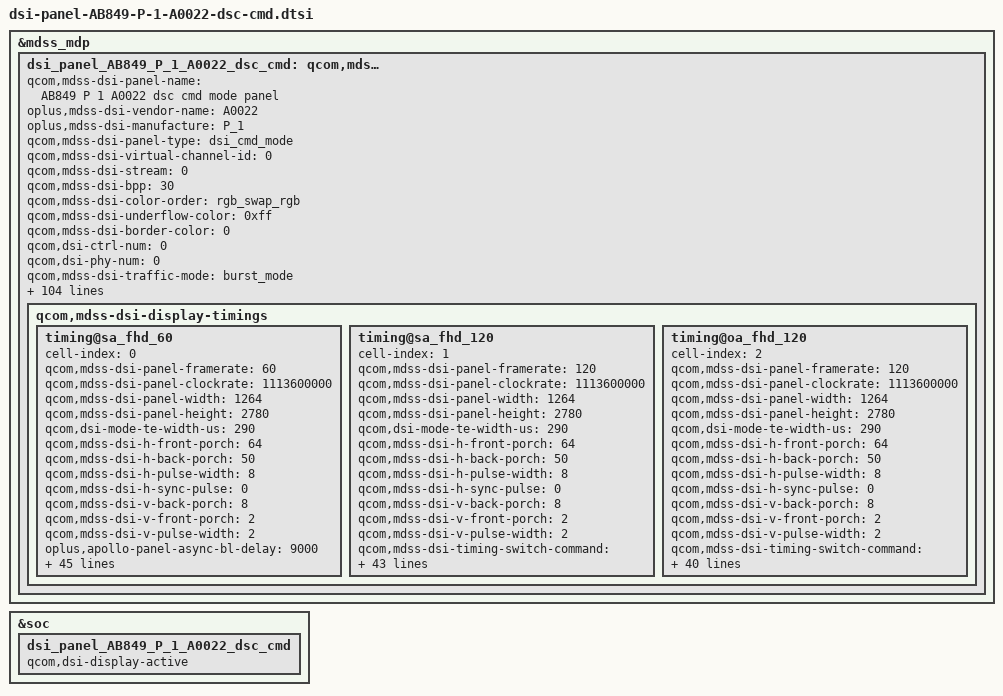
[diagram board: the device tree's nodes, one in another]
&mdss_mdp {
	dsi_panel_AB849_P_1_A0022_dsc_cmd: qcom,mdss_dsi_panel_AB849_P_1_A0022_dsc_cmd {
		qcom,mdss-dsi-panel-name = "AB849 P 1 A0022 dsc cmd mode panel";
		oplus,mdss-dsi-vendor-name = "A0022";
		oplus,mdss-dsi-manufacture = "P_1";
		qcom,mdss-dsi-panel-type = "dsi_cmd_mode";
		qcom,mdss-dsi-virtual-channel-id = <0>;
		qcom,mdss-dsi-stream = <0>;
		qcom,mdss-dsi-bpp = <30>;
		qcom,mdss-dsi-color-order = "rgb_swap_rgb";
		qcom,mdss-dsi-underflow-color = <0xff>;
		qcom,mdss-dsi-border-color = <0>;
		qcom,dsi-ctrl-num = <0>;
		qcom,dsi-phy-num = <0>;
		qcom,mdss-dsi-traffic-mode = "burst_mode";
		qcom,mdss-dsi-lane-map = "lane_map_0123";
		qcom,mdss-dsi-bllp-eof-power-mode;
		qcom,mdss-dsi-bllp-power-mode;
		qcom,mdss-dsi-lane-0-state;
		qcom,mdss-dsi-lane-1-state;
		qcom,mdss-dsi-lane-2-state;
		qcom,mdss-dsi-lane-3-state;
		qcom,mdss-dsi-dma-trigger = "trigger_sw";
		qcom,mdss-dsi-mdp-trigger = "none";
		qcom,mdss-dsi-reset-sequence = <1 10>, <0 5>, <1 20>;
		qcom,mdss-dsi-te-pin-select = <1>;
		qcom,mdss-dsi-te-dcs-command = <1>;
		qcom,mdss-pan-physical-width-dimension = <71>;
		qcom,mdss-pan-physical-height-dimension = <157>;
		qcom,mdss-dsi-init-delay-us = <1000>;
		qcom,mdss-dsi-te-check-enable;
		qcom,mdss-dsi-te-using-te-pin;
		qcom,mdss-dsi-lp11-init;
		qcom,mdss-dsi-wr-mem-start = <0x2c>;
		qcom,mdss-dsi-wr-mem-continue = <0x3c>;
		qcom,mdss-dsi-panel-jitter = <0x4 0x1>;
		qcom,mdss-bl-high2bit;
		/* HDR Setting */
		qcom,mdss-dsi-panel-hdr-enabled;
		qcom,mdss-dsi-panel-hdr-color-primaries = <15635 16450 34000 16000 13250 34500 7500 3000>;
		//update for [MPC15]android.mediapc.cts.PerformanceClassTest#testDisplayHdr pass
		//qcom,mdss-dsi-panel-peak-brightness = <14000000>;
		qcom,mdss-dsi-panel-peak-brightness = <20000000>;
		qcom,mdss-dsi-panel-average-brightness = <2000000>;
		qcom,mdss-dsi-panel-blackness-level = <4000>;
		qcom,mdss-disable-cesta-hw-sleep;

		qcom,mdss-dsi-display-timings {
			timing@sa_fhd_60{
				#include "dsi-panel-AB849-P-1-A0022-common.dtsi"
				//qcom,mdss-mdp-transfer-time-us = <6000>;
				#include "dsi-panel-AB849-P-1-A0022-loading-effect.dtsi"
				cell-index = <0>;
				qcom,mdss-dsi-panel-framerate = <60>;
				qcom,mdss-dsi-panel-clockrate = <1113600000>;
				qcom,mdss-dsi-panel-width = <1264>;
				qcom,mdss-dsi-panel-height = <2780>;
				qcom,dsi-mode-te-width-us = <290>;

				qcom,mdss-dsi-h-front-porch = <64>;
				qcom,mdss-dsi-h-back-porch = <50>;
				qcom,mdss-dsi-h-pulse-width = <8>;
				qcom,mdss-dsi-h-sync-pulse = <0>;
				qcom,mdss-dsi-v-back-porch = <8>;
				qcom,mdss-dsi-v-front-porch = <2>;
				qcom,mdss-dsi-v-pulse-width = <2>;
				oplus,apollo-panel-async-bl-delay = <9000>;

				/* Apollo vsync config, need to measure TE signal */
				oplus,apollo-panel-vsync-width = <9000>;

				qcom,mdss-dsi-timing-switch-command = [
					/* Level 2/3 key Enable */
					39 00 00 40 00 00 03 F0 5A 5A
					39 00 00 40 00 00 03 FC 5A 5A
					/* Sync_TE Setting: Fixed TE */
					39 00 00 40 00 00 04 B0 00 C6 D5
					39 00 00 40 00 00 02 D5 00
					39 00 00 40 00 00 04 B0 00 04 F4
					15 00 00 40 00 00 02 F4 0A
					39 00 00 40 00 00 04 B0 00 DB D5
					39 00 00 40 00 00 05 D5 0B B0 0C 30			/* 0x0B : Fixed TE */
					39 00 00 40 00 00 04 B0 00 E8 D5
					15 00 00 40 00 00 02 D5 01					/* 0x01 : 60Hz */
					/* Frequency Setting */
					39 00 00 40 00 00 03 60 00 09				/* 0x09 : 60Hz(1/18cyc) */
					/* Insert Valid Freq.Setting */
					39 00 00 40 00 00 04 B0 00 88 E4
					39 00 00 40 00 00 05 E4 00 03 00 03
					/* HOP Auto Mode OFF */
					39 00 00 40 00 00 04 B0 00 A9 E4
					15 00 00 40 00 00 02 E4 00					/* 0x00: Auto Off , 0x01: Auto On */
					/* Force Increasing OFF */
					39 00 00 40 00 00 04 B0 00 F4 E4
					15 00 00 40 00 00 02 E4 22					/* 0x00: On , 0x22: Off */
					39 00 00 40 00 00 04 B0 00 65 E4
					39 00 00 40 00 00 06 E4 00 00 00 00 00
					15 00 00 40 00 00 02 F7 0F
					/* Level 2/3 key Disable */
					39 00 00 40 00 00 03 F0 A5 A5
					39 00 00 00 00 00 03 FC A5 A5
				];

				qcom,mdss-dsi-on-command = [
					/* DSC V1.2 Setting 10bit (1264 x 2780, height 139) */
					39 00 00 40 00 00 81 9E 12 00 00 AB 30 80 0A DC 04 F0 00 8B 02 78 02 78 02 00 02 8C 00 20 0B 55 00 08 00 0F 00 DF 00 A1 18 00 11 00 07 10 20 00 06 0F 0F 33 0E 1C 2A 38 46 54 62 69 70 77 79 7B 7D 7E 02 02 22 00 2A 40 2A BE 3A FC 3A FA 3A F8 3B 38 3B 78 3B B6 4B B6 4B F4 4B F4 6C 34 84 74 00 00 00 00 00 00 00 00 00 00 00 00 00 00 00 00 00 00 00 00 00 00 00 00 00 00 00 00 00 00 00 00 00 00 00 00 00 00 00 00
					15 00 00 00 00 00 02 9D 01

					/* Sleep Out(11h) */
					05 00 00 00 66 00 01 11

					/* Common Setting */
					/* TE(Vsync) ON */
					15 00 00 40 00 00 02 35 00
					/* CASET/PASET Setting */
					39 00 00 40 00 00 05 2A 00 00 04 EF
					39 00 00 40 00 00 05 2B 00 00 0A DB
					/* TSP Sync Enable */
					39 00 00 40 00 00 03 F0 5A 5A
					39 00 00 40 00 00 04 B0 00 D8 D5
					15 00 00 40 00 00 02 D5 03
					39 00 00 40 00 00 04 B0 00 C0 D5
					39 00 00 40 00 00 03 D5 06 10
					15 00 00 40 00 00 02 F7 0F
					39 00 00 00 00 00 03 F0 A5 A5
					/* Edge Dimming Code */
					39 00 00 40 00 00 03 F0 5A 5A
					39 00 00 40 00 00 04 B0 00 02 B1
					39 00 00 40 00 00 05 B1 BF BF CF FF
					39 00 00 00 00 00 03 F0 A5 A5
					/* SPR Code */
					39 00 00 40 00 00 03 F0 5A 5A
					39 00 00 40 00 00 04 B0 00 06 B1
					15 00 00 40 00 00 02 B1 50
					39 00 00 40 00 00 03 F0 A5 A5
					/* FFC Code @556.8Mhz, OSC 138.6MHz */
					39 00 00 40 00 00 03 F0 5A 5A
					39 00 00 40 00 00 5B E2 00 80 22 00 00 00 00 00 00 00 00 00 01 90 E4 00 00 00 11 80 00 00 11 80 00 00 11 80 00 00 11 80 00 02 00 14 00 00 0B B8 00 0A 00 A6 00 00 00 00 00 00 00 00 04 04 00 00 00 00 00 00 00 03 00 00 00 04 00 00 27 10 FF FF D8 F0 10 00 00 00 0A 01 04 06 00 00 00 00 00 00 01 00
					39 00 00 40 00 00 02 F7 0F
					39 00 00 00 00 00 03 F0 A5 A5
					/* AOD Sync Setting */
					39 00 00 40 00 00 03 F0 5A 5A
					39 00 00 40 00 00 04 B0 00 92 D4
					15 00 00 40 00 00 02 D4 00
					15 00 00 40 00 00 02 F7 0F
					39 00 00 40 00 00 03 F0 A5 A5
					/* AOD Setting In HOP Mode */
					39 00 00 40 00 00 03 F0 5A 5A
					39 00 00 40 00 00 04 B0 00 C0 EE
					39 00 00 40 00 00 11 EE 05 00 03 00 07 00 03 00 01 00 03 00 03 00 03 00
					15 00 00 40 00 00 02 F7 0F
					39 00 00 00 00 00 03 F0 A5 A5

					/* Brightness Control */
					/* Dimming Setting */
					39 00 00 40 00 00 03 F0 5A 5A
					15 00 00 40 00 00 02 53 20
					39 00 00 40 00 00 03 51 00 00
					39 00 00 40 00 00 03 F0 A5 A5
					/* Level 2/3 key Enable */
					39 00 00 40 00 00 03 F0 5A 5A
					39 00 00 40 00 00 03 FC 5A 5A
					/* Sync_TE Setting: Fixed TE */
					39 00 00 40 00 00 04 B0 00 C6 D5
					39 00 00 40 00 00 02 D5 00
					39 00 00 40 00 00 04 B0 00 04 F4
					15 00 00 40 00 00 02 F4 0A
					39 00 00 40 00 00 04 B0 00 DB D5
					39 00 00 40 00 00 05 D5 0B B0 0C 30			/* 0x0B : Fixed TE */
					39 00 00 40 00 00 04 B0 00 E8 D5
					15 00 00 40 00 00 02 D5 01					/* 0x01 : 60Hz */
					/* Frequency Setting */
					39 00 00 40 00 00 03 60 00 09				/* 0x09 : 60Hz(1cyc) */
					/* Insert Valid Freq.Setting */
					39 00 00 40 00 00 04 B0 00 88 E4
					39 00 00 40 00 00 05 E4 00 03 00 03
					/* HOP Auto Mode OFF */
					39 00 00 40 00 00 04 B0 00 A9 E4
					15 00 00 40 00 00 02 E4 00					/* 0x00: Auto Off , 0x01: Auto On */
					/* Force Increasing OFF */
					39 00 00 40 00 00 04 B0 00 F4 E4
					15 00 00 40 00 00 02 E4 22					/* 0x00: On , 0x22: Off */
					39 00 00 40 00 00 04 B0 00 65 E4
					39 00 00 40 00 00 06 E4 00 00 00 00 00
					15 00 00 40 00 00 02 F7 0F
					/* Level 2/3 key Disable */
					39 00 00 40 00 00 03 F0 A5 A5
					39 00 00 00 00 00 03 FC A5 A5

					/* DBV DIMMING */
					39 00 00 40 00 00 03 F0 5A 5A
					39 00 00 40 00 00 04 B0 00 65 B2
					39 00 00 40 00 00 06 B2 41 C5 1D 41 F1
					39 00 00 40 00 00 04 B0 00 B7 B2
					39 00 00 40 00 00 05 B2 01 5C 01 E8
					39 00 00 40 00 00 04 B0 00 79 B3
					15 00 00 40 00 00 02 B3 06
					39 00 00 00 00 00 03 F0 A5 A5
					/* Laoding On 110% */
					39 00 00 40 00 00 03 F0 5A 5A
					39 00 00 40 00 00 04 B0 00 02 C5
					39 00 00 40 00 00 02 C5 27
					39 00 00 40 00 00 04 B0 00 1B B1
					39 00 00 40 00 00 0F B1 72 92 2B 6D 80 CE A5 D6 AB FF 10 00 00 01
					39 00 00 40 00 00 04 B0 00 20 B1
					39 00 00 40 00 00 05 B1 73 5C D6 AB
					39 00 00 40 00 00 02 F7 0F
					39 00 00 40 00 00 03 F0 A5 A5
					/* PMIC transition period W/A */
					39 00 00 40 00 00 03 F0 5A 5A
					39 00 00 40 00 00 04 B0 00 94 D4
					39 00 00 40 00 00 03 D4 11 00
					39 00 00 40 00 00 02 F7 0F
					39 00 00 00 00 00 03 F0 A5 A5
					/* Solve the problem of mirror display shadow */
					39 00 00 40 00 00 03 F0 5A 5A
					39 00 00 40 00 00 04 B0 00 4A E1
					39 00 00 40 00 00 02 E1 1F
					39 00 00 40 00 00 04 B0 00 4B E1
					39 00 00 40 00 00 0B E1 10 10 10 10 10 10 10 10 10 10
					39 00 00 40 00 00 04 B0 00 55 E1
					39 00 00 40 00 00 0B E1 08 08 08 08 08 08 08 08 08 08
					39 00 00 40 00 00 04 B0 00 6B E1
					39 00 00 40 00 00 0B E1 0C 0C 0C 0C 0C 0C 0C 0C 0C 0C
					39 00 00 40 00 00 04 B0 00 75 E1
					39 00 00 40 00 00 02 E1 FF
					39 00 00 40 00 00 02 F7 0F
					39 00 00 00 00 00 03 F0 A5 A5

					39 00 00 40 00 00 03 F0 5A 5A
					39 00 00 40 00 00 04 B0 00 8D E1
					39 00 00 40 00 00 02 E1 10
					39 00 00 00 00 00 03 F0 A5 A5
					/* display on */
					05 00 00 00 00 00 01 29
				];

				qcom,mdss-dsi-lp1-command = [
					/* AOD 30Hz */
					39 00 00 40 00 00 03 F0 5A 5A
					39 00 00 40 00 00 03 FC 5A 5A
					39 00 00 40 00 00 04 B0 00 C6 D5
					15 00 00 40 00 00 02 D5 00
					39 00 00 40 00 00 04 B0 00 DB D5
					39 00 00 40 00 00 05 D5 0B B0 0C 30
					39 00 00 40 00 00 04 B0 00 E8 D5
					15 00 00 40 00 00 02 D5 00
					39 00 00 40 00 00 04 B0 00 04 F4
					15 00 00 40 00 00 02 F4 0A
					39 00 00 40 00 00 04 B0 00 B2 E4
					39 00 00 40 00 00 03 E4 00 00
					39 00 00 40 00 00 04 B0 00 67 E4
					15 00 00 40 00 00 02 E4 22
					39 00 00 40 00 00 04 B0 00 90 E4
					39 00 00 40 00 00 03 E4 00 00
					39 00 00 40 00 00 04 B0 00 D2 E4
					39 00 00 40 00 00 11 E4 00 00 00 00 00 00 00 00 00 00 00 00 00 00 00 00
					39 00 00 40 00 00 04 B0 00 A9 E4
					15 00 00 40 00 00 02 E4 00
					15 00 00 40 00 00 02 53 24
					39 00 00 40 00 00 03 51 03 DB
					39 00 00 40 00 00 04 B0 00 F4 E4
					15 00 00 40 00 00 02 E4 22
					39 00 00 40 00 00 04 B0 00 65 E4
					39 00 00 40 00 00 06 E4 00 00 00 00 00
					15 00 00 40 00 00 02 F7 0F
					39 00 00 40 00 00 03 FC A5 A5
					39 00 00 00 00 00 03 F0 A5 A5
				];
				qcom,mdss-dsi-nolp-command = [
					/* AOD off */
					39 00 00 40 00 00 03 F0 5A 5A
					39 00 00 40 00 00 03 FC 5A 5A
					39 00 00 40 00 00 04 B0 00 04 F4
					15 00 00 40 00 00 02 F4 0A
					39 00 00 40 00 00 04 B0 00 DB D5
					39 00 00 40 00 00 05 D5 0B B0 0C 30
					39 00 00 40 00 00 04 B0 00 E8 D5
					15 00 00 40 00 00 02 D5 01
					15 00 00 40 00 00 02 53 20
					39 00 00 40 00 00 04 B0 00 A9 E4
					15 00 00 40 00 00 02 E4 00
					39 00 00 40 00 00 04 B0 00 F4 E4
					15 00 00 40 00 00 02 E4 22
					39 00 00 40 00 00 04 B0 00 65 E4
					39 00 00 40 00 00 06 E4 00 00 00 00 00
					15 00 00 40 00 00 02 F7 0F
					39 00 00 40 00 00 03 FC A5 A5
					39 00 00 00 00 00 03 F0 A5 A5
				];
				qcom,mdss-dsi-ultra-low-power-aod-on-command = [
					/* AOD 1Hz */
					39 00 00 40 00 00 03 F0 5A 5A
					39 00 00 40 00 00 03 FC 5A 5A
					39 00 00 40 00 00 04 B0 00 C6 D5
					15 00 00 40 00 00 02 D5 00
					39 00 00 40 00 00 04 B0 00 04 F4
					15 00 00 40 00 00 02 F4 0A
					39 00 00 40 00 00 04 B0 00 DB D5
					39 00 00 40 00 00 05 D5 0B B0 0C 30
					39 00 00 40 00 00 04 B0 00 E8 D5
					15 00 00 40 00 00 02 D5 00
					39 00 00 40 00 00 04 B0 00 B2 E4
					39 00 00 40 00 00 03 E4 00 74
					39 00 00 40 00 00 04 B0 00 67 E4
					15 00 00 40 00 00 02 E4 22
					39 00 00 40 00 00 04 B0 00 90 E4
					39 00 00 40 00 00 03 E4 00 00
					39 00 00 40 00 00 04 B0 00 D2 E4
					39 00 00 40 00 00 11 E4 00 00 00 74 00 74 00 74 00 74 00 74 00 74 00 74
					39 00 00 40 00 00 04 B0 00 A9 E4
					15 00 00 40 00 00 02 E4 01
					15 00 00 40 00 00 02 53 24
					39 00 00 40 00 00 04 B0 00 F4 E4
					15 00 00 40 00 00 02 E4 00
					39 00 00 40 00 00 04 B0 00 65 E4
					39 00 00 40 00 00 06 E4 22 22 22 22 22
					15 00 00 40 00 00 02 F7 0F
					39 00 00 40 00 00 03 FC A5 A5
					39 00 00 00 00 00 03 F0 A5 A5
				];
				qcom,mdss-dsi-ultra-low-power-aod-off-command = [
					/* AOD 1Hz OFF, use AOD 30Hz */
					39 00 00 40 00 00 03 F0 5A 5A
					39 00 00 40 00 00 03 FC 5A 5A
					39 00 00 40 00 00 04 B0 00 C6 D5
					15 00 00 40 00 00 02 D5 00
					39 00 00 40 00 00 04 B0 00 04 F4
					15 00 00 40 00 00 02 F4 0A
					39 00 00 40 00 00 04 B0 00 B2 E4
					39 00 00 40 00 00 03 E4 00 00
					39 00 00 40 00 00 04 B0 00 67 E4
					15 00 00 40 00 00 02 E4 22
					39 00 00 40 00 00 04 B0 00 90 E4
					39 00 00 40 00 00 03 E4 00 00
					39 00 00 40 00 00 04 B0 00 D2 E4
					39 00 00 40 00 00 11 E4 00 00 00 00 00 00 00 00 00 00 00 00 00 00 00 00
					39 00 00 40 00 00 04 B0 00 A9 E4
					15 00 00 40 00 00 02 E4 00
					15 00 00 40 00 00 02 53 24
					39 00 00 40 00 00 04 B0 00 F4 E4
					15 00 00 40 00 00 02 E4 22
					39 00 00 40 00 00 04 B0 00 65 E4
					39 00 00 40 00 00 06 E4 00 00 00 00 00
					15 00 00 40 00 00 02 F7 0F
					39 00 00 40 00 00 03 FC A5 A5
					39 00 00 00 00 00 03 F0 A5 A5
				];

				/* standard adfr */
				qcom,mdss-dsi-h-sync-skew = <1>;
				oplus,adfr-min-fps-mapping-table = <60 10 1>;
				//oplus,adfr-idle-off-min-fps = <20>;
				//Big DC Mode
				qcom,mdss-dsi-hpwm-adfr-min-fps-0-command = [
					/* 60Hz */
					/* Level 2/3 key Enable */
					39 00 00 40 00 00 03 F0 5A 5A
					39 00 00 40 00 00 03 FC 5A 5A
					/* HOP Auto Mode OFF */
					39 00 00 40 00 00 04 B0 00 B0 E4			/* Target Freq.Setting */
					39 00 00 40 00 00 03 E4 00 01				/* BASE 120Hz(1CYC.) Low Freq. Setting, 0x00, 0x01 : 60Hz */
					39 00 00 40 00 00 04 B0 00 88 E4
					39 00 00 40 00 00 05 E4 00 03 00 03			/* Insert Valid Freq.Setting */
					39 00 00 40 00 00 04 B0 00 BA E4
					39 00 00 40 00 00 11 E4 00 01 00 03 00 0B 00 0B 00 17 00 17 00 17 00 77	/* Step Delay Freq. 120-30-10-10-5-5-5-1 */
					39 00 00 40 00 00 04 B0 00 A9 E4
					15 00 00 40 00 00 02 E4 00					/* 0x00: Auto Off , 0x01: Auto On */
					/* Force Increasing OFF */
					39 00 00 40 00 00 04 B0 00 F4 E4
					15 00 00 40 00 00 02 E4 22					/* 0x00: On , 0x22: Off */
					39 00 00 40 00 00 04 B0 00 65 E4
					39 00 00 40 00 00 06 E4 00 00 00 00 00
					15 00 00 40 00 00 02 F7 0F
					/* Level 2/3 key Disable */
					39 00 00 40 00 00 03 F0 A5 A5
					39 00 00 00 00 00 03 FC A5 A5
				];
				qcom,mdss-dsi-hpwm-adfr-min-fps-1-command = [
					/* 10Hz */
					/* Level 2/3 key Enable */
					39 00 00 40 00 00 03 F0 5A 5A
					39 00 00 40 00 00 03 FC 5A 5A
					/* HOP Auto Mode ON*/
					39 00 00 40 00 00 04 B0 00 B0 E4			/* Target Freq.Setting */
					39 00 00 40 00 00 03 E4 00 0B				/* BASE 120Hz(1CYC.) Low Freq. Setting, 0x00, 0x0B : 10Hz */
					39 00 00 40 00 00 04 B0 00 88 E4
					39 00 00 40 00 00 05 E4 00 03 00 03			/* Insert Valid Freq.Setting */
					39 00 00 40 00 00 04 B0 00 BA E4
					39 00 00 40 00 00 11 E4 00 01 00 03 00 0B 00 0B 00 0B 00 0B 00 0B 00 0B	/* Step Delay Freq. 120-30-10-10-10-10-10-10 */
					39 00 00 40 00 00 04 B0 00 A9 E4
					15 00 00 40 00 00 02 E4 01					/* 0x00: Auto Off , 0x01: Auto On */
					/* Force Increasing ON */
					39 00 00 40 00 00 04 B0 00 F4 E4
					15 00 00 40 00 00 02 E4 00					/* 0x00: On , 0x22: Off */
					39 00 00 40 00 00 04 B0 00 65 E4
					39 00 00 40 00 00 06 E4 22 22 22 22 22
					15 00 00 40 00 00 02 F7 0F
					/* Level 2/3 key Disable */
					39 00 00 40 00 00 03 F0 A5 A5
					39 00 00 00 00 00 03 FC A5 A5
				];
				qcom,mdss-dsi-hpwm-adfr-min-fps-2-command = [
					/* 1Hz */
					/* Level 2/3 key Enable */
					39 00 00 40 00 00 03 F0 5A 5A
					39 00 00 40 00 00 03 FC 5A 5A
					/* HOP Auto Mode ON*/
					39 00 00 40 00 00 04 B0 00 B0 E4			/* Target Freq.Setting */
					39 00 00 40 00 00 03 E4 00 77				/* BASE 120Hz(1CYC.) Low Freq. Setting, 0x00, 0x77 : 1Hz */
					39 00 00 40 00 00 04 B0 00 88 E4
					39 00 00 40 00 00 05 E4 00 03 00 03			/* Insert Valid Freq.Setting */
					39 00 00 40 00 00 04 B0 00 BA E4
					39 00 00 40 00 00 11 E4 00 01 00 03 00 0B 00 0B 00 17 00 17 00 17 00 77	/* Step Delay Freq. 120-30-10-10-5-5-5-1 */
					39 00 00 40 00 00 04 B0 00 A9 E4
					15 00 00 40 00 00 02 E4 01					/* 0x00: Auto Off , 0x01: Auto On */
					/* Force Increasing ON */
					39 00 00 40 00 00 04 B0 00 F4 E4
					15 00 00 40 00 00 02 E4 00					/* 0x00: On , 0x22: Off */
					39 00 00 40 00 00 04 B0 00 65 E4
					39 00 00 40 00 00 06 E4 22 22 22 22 22
					15 00 00 40 00 00 02 F7 0F
					/* Level 2/3 key Disable */
					39 00 00 40 00 00 03 F0 A5 A5
					39 00 00 00 00 00 03 FC A5 A5
				];
				//1pulse
				qcom,mdss-dsi-bigdc-adfr-min-fps-0-command = [
					/* 60Hz */
					/* Level 2/3 key Enable */
					39 00 00 40 00 00 03 F0 5A 5A
					39 00 00 40 00 00 03 FC 5A 5A
					/* HOP Auto Mode OFF */
					39 00 00 40 00 00 04 B0 00 B0 E4			/* Target Freq.Setting */
					39 00 00 40 00 00 03 E4 00 01				/* BASE 120Hz(1CYC.) Low Freq. Setting, 0x00, 0x01 : 60Hz */
					39 00 00 40 00 00 04 B0 00 88 E4
					39 00 00 40 00 00 05 E4 00 03 00 03			/* Insert Valid Freq.Setting */
					39 00 00 40 00 00 04 B0 00 BA E4
					39 00 00 40 00 00 11 E4 00 01 00 03 00 0B 00 0B 00 17 00 17 00 17 00 77	/* Step Delay Freq. 120-30-10-10-5-5-5-1 */
					39 00 00 40 00 00 04 B0 00 A9 E4
					15 00 00 40 00 00 02 E4 00					/* 0x00: Auto Off , 0x01: Auto On */
					/* Force Increasing OFF */
					39 00 00 40 00 00 04 B0 00 F4 E4
					15 00 00 40 00 00 02 E4 22					/* 0x00: On , 0x22: Off */
					39 00 00 40 00 00 04 B0 00 65 E4
					39 00 00 40 00 00 06 E4 00 00 00 00 00
					15 00 00 40 00 00 02 F7 0F
					/* Level 2/3 key Disable */
					39 00 00 40 00 00 03 F0 A5 A5
					39 00 00 00 00 00 03 FC A5 A5
				];
				qcom,mdss-dsi-bigdc-adfr-min-fps-1-command = [
					/* 10Hz */
					/* Level 2/3 key Enable */
					39 00 00 40 00 00 03 F0 5A 5A
					39 00 00 40 00 00 03 FC 5A 5A
					/* HOP Auto Mode ON*/
					39 00 00 40 00 00 04 B0 00 B0 E4			/* Target Freq.Setting */
					39 00 00 40 00 00 03 E4 00 0B				/* BASE 120Hz(1CYC.) Low Freq. Setting, 0x00, 0x0B : 10Hz */
					39 00 00 40 00 00 04 B0 00 88 E4
					39 00 00 40 00 00 05 E4 00 03 00 03			/* Insert Valid Freq.Setting */
					39 00 00 40 00 00 04 B0 00 BA E4
					39 00 00 40 00 00 11 E4 00 01 00 03 00 0B 00 0B 00 0B 00 0B 00 0B 00 0B	/* Step Delay Freq. 120-30-10-10-10-10-10-10 */
					39 00 00 40 00 00 04 B0 00 A9 E4
					15 00 00 40 00 00 02 E4 01					/* 0x00: Auto Off , 0x01: Auto On */
					/* Force Increasing ON */
					39 00 00 40 00 00 04 B0 00 F4 E4
					15 00 00 40 00 00 02 E4 00					/* 0x00: On , 0x22: Off */
					39 00 00 40 00 00 04 B0 00 65 E4
					39 00 00 40 00 00 06 E4 22 22 22 22 22
					15 00 00 40 00 00 02 F7 0F
					/* Level 2/3 key Disable */
					39 00 00 40 00 00 03 F0 A5 A5
					39 00 00 00 00 00 03 FC A5 A5
				];
				qcom,mdss-dsi-bigdc-adfr-min-fps-2-command = [
					/* 1Hz */
					/* Level 2/3 key Enable */
					39 00 00 40 00 00 03 F0 5A 5A
					39 00 00 40 00 00 03 FC 5A 5A
					/* HOP Auto Mode ON*/
					39 00 00 40 00 00 04 B0 00 B0 E4			/* Target Freq.Setting */
					39 00 00 40 00 00 03 E4 00 77				/* BASE 120Hz(1CYC.) Low Freq. Setting, 0x00, 0x77 : 1Hz */
					39 00 00 40 00 00 04 B0 00 88 E4
					39 00 00 40 00 00 05 E4 00 03 00 03			/* Insert Valid Freq.Setting */
					39 00 00 40 00 00 04 B0 00 BA E4
					39 00 00 40 00 00 11 E4 00 01 00 03 00 0B 00 0B 00 17 00 17 00 17 00 77	/* Step Delay Freq. 120-30-10-10-5-5-5-1 */
					39 00 00 40 00 00 04 B0 00 A9 E4
					15 00 00 40 00 00 02 E4 01					/* 0x00: Auto Off , 0x01: Auto On */
					/* Force Increasing ON */
					39 00 00 40 00 00 04 B0 00 F4 E4
					15 00 00 40 00 00 02 E4 00					/* 0x00: On , 0x22: Off */
					39 00 00 40 00 00 04 B0 00 65 E4
					39 00 00 40 00 00 06 E4 22 22 22 22 22
					15 00 00 40 00 00 02 F7 0F
					/* Level 2/3 key Disable */
					39 00 00 40 00 00 03 F0 A5 A5
					39 00 00 00 00 00 03 FC A5 A5
				];
				qcom,mdss-dsi-pwm-state-l1tol3-command = [
					39 00 00 40 00 00 03 F0 5A 5A
					39 00 00 40 00 00 04 B0 00 D7 BF
					15 00 00 40 00 00 02 BF 01
					39 00 00 40 00 00 04 B0 00 9A C0
					39 00 00 40 00 00 61 C0 00 04 08 10 18 20 28 38 40 50 60 70 80 90 A0 B0 C0 D0 E0 E8 F0 F8 FC FE FF FF FF FF FF FF FF FF 00 04 08 10 18 20 28 38 40 50 60 70 80 90 A0 B0 C0 D0 E0 E8 F0 F8 FC FE FF FF FF FF FF FF FF FF 00 04 08 10 18 20 28 38 40 50 60 70 80 90 A0 B0 C0 D0 E0 E8 F0 F8 FC FE FF FF FF FF FF FF FF FF
					39 00 00 40 00 00 04 B0 00 D8 BF
					39 00 00 40 00 00 27 BF 00 00 3F EC 3F CE 3F CE 3F 9C 3F 9C 3F B0 3F 9C 3F D8 00 58 00 58 00 48 00 58 00 48 00 58 00 58 00 40 00 58 00 58
					39 00 00 40 00 00 1B C0 00 58 00 58 00 58 00 58 00 58 00 58 00 58 00 58 00 58 00 58 00 58 00 58 00 58
					39 00 00 40 00 00 04 B0 00 1A C0
					39 00 00 40 00 00 41 C0 00 00 3F EC 3F CE 3F CE 3F 9C 3F 9C 3F B0 3F 9C 3F D8 00 58 00 58 00 48 00 58 00 48 00 58 00 58 00 40 00 58 00 58 00 58 00 58 00 58 00 58 00 58 00 58 00 58 00 58 00 58 00 58 00 58 00 58 00 58
					39 00 00 40 00 00 04 B0 00 5A C0
					39 00 00 40 00 00 41 C0 00 00 3F EC 3F CE 3F CE 3F 9C 3F 9C 3F B0 3F 9C 3F D8 00 58 00 58 00 48 00 58 00 48 00 58 00 58 00 40 00 58 00 58 00 58 00 58 00 58 00 58 00 58 00 58 00 58 00 58 00 58 00 58 00 58 00 58 00 58
					15 00 00 40 00 00 02 F7 0F
					39 00 00 00 00 00 03 F0 A5 A5
				];
				qcom,mdss-dsi-pwm-state-l3tol1-command = [
					39 00 00 40 00 00 03 F0 5A 5A
					39 00 00 40 00 00 04 B0 00 D7 BF
					15 00 00 40 00 00 02 BF 01
					39 00 00 40 00 00 04 B0 00 9A C0
					39 00 00 40 00 00 61 C0 00 04 08 10 18 20 28 38 48 58 68 78 88 98 A8 B8 C8 D8 E8 EC FC FE FF FF FF FF FF FF FF FF FF FF 00 04 08 10 18 20 28 38 48 58 68 78 88 98 A8 B8 C8 D8 E8 EC FC FE FF FF FF FF FF FF FF FF FF FF 00 04 08 10 18 20 28 38 48 58 68 78 88 98 A8 B8 C8 D8 E8 EC FC FE FF FF FF FF FF FF FF FF FF FF
					39 00 00 40 00 00 04 B0 00 D8 BF
					39 00 00 40 00 00 27 BF 00 00 00 01 00 01 00 01 00 01 00 01 00 01 3F EC 3F F6 3F DD 3F DD 3F C9 3F E4 3F E4 3F C4 3F CE 3F CE 3F CE 3F CE
					39 00 00 40 00 00 1B C0 3F CE 3F CE 3F CE 3F CE 3F CE 3F CE 3F CE 3F CE 3F CE 3F CE 3F CE 3F CE 3F CE
					39 00 00 40 00 00 04 B0 00 1A C0
					39 00 00 40 00 00 41 C0 00 00 00 01 00 01 00 01 00 01 00 01 00 01 3F EC 3F F6 3F DD 3F DD 3F C9 3F E4 3F E4 3F C4 3F CE 3F CE 3F CE 3F CE 3F CE 3F CE 3F CE 3F CE 3F CE 3F CE 3F CE 3F CE 3F CE 3F CE 3F CE 3F CE 3F CE
					39 00 00 40 00 00 04 B0 00 5A C0
					39 00 00 40 00 00 41 C0 00 00 00 01 00 01 00 01 00 01 00 01 00 01 3F EC 3F F6 3F DD 3F DD 3F C9 3F E4 3F E4 3F C4 3F E4 3F E4 3F E4 3F E4 3F E4 3F E4 3F E4 3F E4 3F E4 3F E4 3F E4 3F E4 3F E4 3F E4 3F E4 3F E4 3F E4
					15 00 00 40 00 00 02 F7 0F
					39 00 00 00 00 00 03 F0 A5 A5
				];
				qcom,mdss-dsi-pwm-dbv-threshold-extend-command = [
					39 00 00 40 00 00 03 F0 5A 5A
					39 00 00 40 00 00 04 B0 00 D7 BF
					15 00 00 40 00 00 02 BF 00
					15 00 00 40 00 00 02 F7 0F
					39 00 00 00 00 00 03 F0 A5 A5
				];

				qcom,mdss-dsi-timming-pwm-switch-onepulse-command = [
					/* Level 2/3 key Enable */
					39 00 00 40 00 00 03 F0 5A 5A
					39 00 00 40 00 00 03 FC 5A 5A
					/* Sync_TE Setting: Fixed TE */
					39 00 00 40 00 00 04 B0 00 C6 D5
					39 00 00 40 00 00 02 D5 00
					39 00 00 40 00 00 04 B0 00 04 F4
					15 00 00 40 00 00 02 F4 0A
					39 00 00 40 00 00 04 B0 00 DB D5
					39 00 00 40 00 00 05 D5 0B B0 0C 30			/* 0x0B : Fixed TE */
					39 00 00 40 00 00 04 B0 00 E8 D5
					15 00 00 40 00 00 02 D5 01					/* 0x01 : 60Hz */
					/* Frequency Setting */
					39 00 00 40 00 00 03 60 00 01				/* 0x09 : 60Hz(1cyc) */
					/* Insert Valid Freq.Setting */
					39 00 00 40 00 00 04 B0 00 88 E4
					39 00 00 40 00 00 05 E4 00 03 00 03
					/* HOP Auto Mode OFF */
					39 00 00 40 00 00 04 B0 00 A9 E4
					15 00 00 40 00 00 02 E4 00					/* 0x00: Auto Off , 0x01: Auto On */
					/* Force Increasing OFF */
					39 00 00 40 00 00 04 B0 00 F4 E4
					15 00 00 40 00 00 02 E4 22					/* 0x00: On , 0x22: Off */
					39 00 00 40 00 00 04 B0 00 65 E4
					39 00 00 40 00 00 06 E4 00 00 00 00 00
					15 00 00 40 00 00 02 F7 0F
					/* Level 2/3 key Disable */
					39 00 00 40 00 00 03 F0 A5 A5
					39 00 00 00 00 00 03 FC A5 A5
				];
				qcom,mdss-dsi-pwm-switch-mode0-command = [
					/* Level 2/3 key Enable */
					39 00 00 40 00 00 03 F0 5A 5A
					39 00 00 40 00 00 03 FC 5A 5A
					/* Sync_TE Setting: Fixed TE */
					39 00 00 40 00 00 04 B0 00 C6 D5
					39 00 00 40 00 00 02 D5 00
					39 00 00 40 00 00 04 B0 00 04 F4
					15 00 00 40 00 00 02 F4 0A
					39 00 00 40 00 00 04 B0 00 DB D5
					39 00 00 40 00 00 05 D5 0B B0 0C 30			/* 0x0B : Fixed TE */
					39 00 00 40 00 00 04 B0 00 E8 D5
					15 00 00 40 00 00 02 D5 01					/* 0x01 : 60Hz */
					/* Frequency Setting */
					39 00 00 40 00 00 03 60 00 09				/* 0x09 : 60Hz(1/18cyc) */
					/* HOP Auto Mode OFF */
					39 00 00 40 00 00 04 B0 00 A9 E4
					15 00 00 40 00 00 02 E4 00					/* 0x00: Auto Off , 0x01: Auto On */
					/* Force Increasing OFF */
					39 00 00 40 00 00 04 B0 00 F4 E4
					15 00 00 40 00 00 02 E4 22					/* 0x00: On , 0x22: Off */
					39 00 00 40 00 00 04 B0 00 65 E4
					39 00 00 40 00 00 06 E4 00 00 00 00 00
					15 00 00 40 00 00 02 F7 0F
					/* Level 2/3 key Disable */
					39 00 00 40 00 00 03 F0 A5 A5
					39 00 00 00 00 00 03 FC A5 A5
				];
				qcom,mdss-dsi-pwm-switch-mode1-command = [
					/* Level 2/3 key Enable */
					39 00 00 40 00 00 03 F0 5A 5A
					39 00 00 40 00 00 03 FC 5A 5A
					/* Sync_TE Setting: Fixed TE */
					39 00 00 40 00 00 04 B0 00 C6 D5
					39 00 00 40 00 00 02 D5 00
					39 00 00 40 00 00 04 B0 00 04 F4
					15 00 00 40 00 00 02 F4 0A
					39 00 00 40 00 00 04 B0 00 DB D5
					39 00 00 40 00 00 05 D5 0B B0 0C 30			/* 0x0B : Fixed TE */
					39 00 00 40 00 00 04 B0 00 E8 D5
					15 00 00 40 00 00 02 D5 01					/* 0x01 : 60Hz */
					/* Frequency Setting */
					39 00 00 40 00 00 03 60 00 01				/* 0x09 : 60Hz(1cyc) */
					/* HOP Auto Mode OFF */
					39 00 00 40 00 00 04 B0 00 A9 E4
					15 00 00 40 00 00 02 E4 00					/* 0x00: Auto Off , 0x01: Auto On */
					/* Force Increasing OFF */
					39 00 00 40 00 00 04 B0 00 F4 E4
					15 00 00 40 00 00 02 E4 22					/* 0x00: On , 0x22: Off */
					39 00 00 40 00 00 04 B0 00 65 E4
					39 00 00 40 00 00 06 E4 00 00 00 00 00
					15 00 00 40 00 00 02 F7 0F
					/* Level 2/3 key Disable */
					39 00 00 40 00 00 03 F0 A5 A5
					39 00 00 00 00 00 03 FC A5 A5
				];
				qcom,mdss-dsi-pwm-switch-mode1-panel-on-command = [
					/* Level 2/3 key Enable */
					39 00 00 40 00 00 03 F0 5A 5A
					39 00 00 40 00 00 03 FC 5A 5A
					/* Sync_TE Setting: Fixed TE */
					39 00 00 40 00 00 04 B0 00 C6 D5
					39 00 00 40 00 00 02 D5 00
					39 00 00 40 00 00 04 B0 00 04 F4
					15 00 00 40 00 00 02 F4 0A
					39 00 00 40 00 00 04 B0 00 DB D5
					39 00 00 40 00 00 05 D5 0B B0 0C 30			/* 0x0B : Fixed TE */
					39 00 00 40 00 00 04 B0 00 E8 D5
					15 00 00 40 00 00 02 D5 01					/* 0x01 : 60Hz */
					/* Frequency Setting */
					39 00 00 40 00 00 03 60 00 01				/* 0x09 : 60Hz(1cyc) */
					/* HOP Auto Mode OFF */
					39 00 00 40 00 00 04 B0 00 A9 E4
					15 00 00 40 00 00 02 E4 00					/* 0x00: Auto Off , 0x01: Auto On */
					/* Force Increasing OFF */
					39 00 00 40 00 00 04 B0 00 F4 E4
					15 00 00 40 00 00 02 E4 22					/* 0x00: On , 0x22: Off */
					39 00 00 40 00 00 04 B0 00 65 E4
					39 00 00 40 00 00 06 E4 00 00 00 00 00
					15 00 00 40 00 00 02 F7 0F
					/* Level 2/3 key Disable */
					39 00 00 40 00 00 03 F0 A5 A5
					39 00 00 00 00 00 03 FC A5 A5
				];

			};
			timing@sa_fhd_120{
				#include "dsi-panel-AB849-P-1-A0022-common.dtsi"
				//qcom,mdss-mdp-transfer-time-us = <6000>;
				#include "dsi-panel-AB849-P-1-A0022-loading-effect.dtsi"
				cell-index = <1>;
				qcom,mdss-dsi-panel-framerate = <120>;
				qcom,mdss-dsi-panel-clockrate = <1113600000>;
				qcom,mdss-dsi-panel-width = <1264>;
				qcom,mdss-dsi-panel-height = <2780>;
				qcom,dsi-mode-te-width-us = <290>;

				qcom,mdss-dsi-h-front-porch = <64>;
				qcom,mdss-dsi-h-back-porch = <50>;
				qcom,mdss-dsi-h-pulse-width = <8>;
				qcom,mdss-dsi-h-sync-pulse = <0>;
				qcom,mdss-dsi-v-back-porch = <8>;
				qcom,mdss-dsi-v-front-porch = <2>;
				qcom,mdss-dsi-v-pulse-width = <2>;

				qcom,mdss-dsi-timing-switch-command = [
					/* Level 2/3 key Enable */
					39 00 00 40 00 00 03 F0 5A 5A
					39 00 00 40 00 00 03 FC 5A 5A
					/* Sync_TE Setting: Fixed TE */
					39 00 00 40 00 00 04 B0 00 C6 D5
					39 00 00 40 00 00 02 D5 00
					39 00 00 40 00 00 04 B0 00 04 F4
					15 00 00 40 00 00 02 F4 0A
					39 00 00 40 00 00 04 B0 00 DB D5
					39 00 00 40 00 00 05 D5 0B B0 0C 30			/* 0x0B : Fixed TE */
					39 00 00 40 00 00 04 B0 00 E8 D5
					15 00 00 40 00 00 02 D5 00					/* 0x00 : 120Hz */
					/* Frequency Setting */
					39 00 00 40 00 00 03 60 00 08				/* 0x08 : 120Hz(1/18cyc) */
					/* Insert Valid Freq.Setting */
					39 00 00 40 00 00 04 B0 00 88 E4
					39 00 00 40 00 00 05 E4 00 03 00 03
					/* HOP Auto Mode OFF */
					39 00 00 40 00 00 04 B0 00 A9 E4
					15 00 00 40 00 00 02 E4 00					/* 0x00: Auto Off , 0x01: Auto On */
					/* Force Increasing OFF */
					39 00 00 40 00 00 04 B0 00 F4 E4
					15 00 00 40 00 00 02 E4 22					/* 0x00: On , 0x22: Off */
					39 00 00 40 00 00 04 B0 00 65 E4
					39 00 00 40 00 00 06 E4 00 00 00 00 00
					15 00 00 40 00 00 02 F7 0F
					/* Level 2/3 key Disable */
					39 00 00 40 00 00 03 F0 A5 A5
					39 00 00 00 00 00 03 FC A5 A5
				];

				qcom,mdss-dsi-on-command = [
					/* DSC V1.2 Setting 10bit (1264 x 2780, height 139) */
					39 00 00 40 00 00 81 9E 12 00 00 AB 30 80 0A DC 04 F0 00 8B 02 78 02 78 02 00 02 8C 00 20 0B 55 00 08 00 0F 00 DF 00 A1 18 00 11 00 07 10 20 00 06 0F 0F 33 0E 1C 2A 38 46 54 62 69 70 77 79 7B 7D 7E 02 02 22 00 2A 40 2A BE 3A FC 3A FA 3A F8 3B 38 3B 78 3B B6 4B B6 4B F4 4B F4 6C 34 84 74 00 00 00 00 00 00 00 00 00 00 00 00 00 00 00 00 00 00 00 00 00 00 00 00 00 00 00 00 00 00 00 00 00 00 00 00 00 00 00 00
					15 00 00 00 00 00 02 9D 01

					/* Sleep Out(11h) */
					05 00 00 00 66 00 01 11

					/* Common Setting */
					/* TE(Vsync) ON */
					15 00 00 40 00 00 02 35 00
					/* CASET/PASET Setting */
					39 00 00 40 00 00 05 2A 00 00 04 EF
					39 00 00 40 00 00 05 2B 00 00 0A DB
					/* TSP Sync Enable */
					39 00 00 40 00 00 03 F0 5A 5A
					39 00 00 40 00 00 04 B0 00 D8 D5
					15 00 00 40 00 00 02 D5 03
					39 00 00 40 00 00 04 B0 00 C0 D5
					39 00 00 40 00 00 03 D5 06 10
					15 00 00 40 00 00 02 F7 0F
					39 00 00 00 00 00 03 F0 A5 A5
					/* Edge Dimming Code */
					39 00 00 40 00 00 03 F0 5A 5A
					39 00 00 40 00 00 04 B0 00 02 B1
					39 00 00 40 00 00 05 B1 BF BF CF FF
					39 00 00 00 00 00 03 F0 A5 A5
					/* SPR Code */
					39 00 00 40 00 00 03 F0 5A 5A
					39 00 00 40 00 00 04 B0 00 06 B1
					15 00 00 40 00 00 02 B1 50
					39 00 00 40 00 00 03 F0 A5 A5
					/* FFC Code @556.8Mhz, OSC 138.6MHz */
					39 00 00 40 00 00 03 F0 5A 5A
					39 00 00 40 00 00 5B E2 00 80 22 00 00 00 00 00 00 00 00 00 01 90 E4 00 00 00 11 80 00 00 11 80 00 00 11 80 00 00 11 80 00 02 00 14 00 00 0B B8 00 0A 00 A6 00 00 00 00 00 00 00 00 04 04 00 00 00 00 00 00 00 03 00 00 00 04 00 00 27 10 FF FF D8 F0 10 00 00 00 0A 01 04 06 00 00 00 00 00 00 01 00
					39 00 00 40 00 00 02 F7 0F
					39 00 00 00 00 00 03 F0 A5 A5
					/* AOD Sync Setting */
					39 00 00 40 00 00 03 F0 5A 5A
					39 00 00 40 00 00 04 B0 00 92 D4
					15 00 00 40 00 00 02 D4 00
					15 00 00 40 00 00 02 F7 0F
					39 00 00 40 00 00 03 F0 A5 A5
					/* AOD Setting In HOP Mode */
					39 00 00 40 00 00 03 F0 5A 5A
					39 00 00 40 00 00 04 B0 00 C0 EE
					39 00 00 40 00 00 11 EE 05 00 03 00 07 00 03 00 01 00 03 00 03 00 03 00
					15 00 00 40 00 00 02 F7 0F
					39 00 00 00 00 00 03 F0 A5 A5

					/* Brightness Control */
					/* Dimming Setting */
					39 00 00 40 00 00 03 F0 5A 5A
					15 00 00 40 00 00 02 53 20
					39 00 00 40 00 00 03 51 00 00
					39 00 00 40 00 00 03 F0 A5 A5
					/* Level 2/3 key Enable */
					39 00 00 40 00 00 03 F0 5A 5A
					39 00 00 40 00 00 03 FC 5A 5A
					/* Sync_TE Setting: Fixed TE */
					39 00 00 40 00 00 04 B0 00 C6 D5
					39 00 00 40 00 00 02 D5 00
					39 00 00 40 00 00 04 B0 00 04 F4
					15 00 00 40 00 00 02 F4 0A
					39 00 00 40 00 00 04 B0 00 DB D5
					39 00 00 40 00 00 05 D5 0B B0 0C 30			/* 0x0B : Fixed TE */
					39 00 00 40 00 00 04 B0 00 E8 D5
					15 00 00 40 00 00 02 D5 00					/* 0x00 : 120Hz */
					/* Frequency Setting */
					39 00 00 40 00 00 03 60 00 08				/* 0x08 : 120Hz(1cyc) */
					/* Insert Valid Freq.Setting */
					39 00 00 40 00 00 04 B0 00 88 E4
					39 00 00 40 00 00 05 E4 00 03 00 03
					/* HOP Auto Mode OFF */
					39 00 00 40 00 00 04 B0 00 A9 E4
					15 00 00 40 00 00 02 E4 00					/* 0x00: Auto Off , 0x01: Auto On */
					/* Force Increasing OFF */
					39 00 00 40 00 00 04 B0 00 F4 E4
					15 00 00 40 00 00 02 E4 22					/* 0x00: On , 0x22: Off */
					39 00 00 40 00 00 04 B0 00 65 E4
					39 00 00 40 00 00 06 E4 00 00 00 00 00
					15 00 00 40 00 00 02 F7 0F
					/* Level 2/3 key Disable */
					39 00 00 40 00 00 03 F0 A5 A5
					39 00 00 00 00 00 03 FC A5 A5

					/* DBV DIMMING */
					39 00 00 40 00 00 03 F0 5A 5A
					39 00 00 40 00 00 04 B0 00 65 B2
					39 00 00 40 00 00 06 B2 41 C5 1D 41 F1
					39 00 00 40 00 00 04 B0 00 B7 B2
					39 00 00 40 00 00 05 B2 01 5C 01 E8
					39 00 00 40 00 00 04 B0 00 79 B3
					15 00 00 40 00 00 02 B3 06
					39 00 00 00 00 00 03 F0 A5 A5
					/* Laoding On 110% */
					39 00 00 40 00 00 03 F0 5A 5A
					39 00 00 40 00 00 04 B0 00 02 C5
					39 00 00 40 00 00 02 C5 27
					39 00 00 40 00 00 04 B0 00 1B B1
					39 00 00 40 00 00 0F B1 72 92 2B 6D 80 CE A5 D6 AB FF 10 00 00 01
					39 00 00 40 00 00 04 B0 00 20 B1
					39 00 00 40 00 00 05 B1 73 5C D6 AB
					39 00 00 40 00 00 02 F7 0F
					39 00 00 40 00 00 03 F0 A5 A5
					/* PMIC transition period W/A */
					39 00 00 40 00 00 03 F0 5A 5A
					39 00 00 40 00 00 04 B0 00 94 D4
					39 00 00 40 00 00 03 D4 11 00
					39 00 00 40 00 00 02 F7 0F
					39 00 00 00 00 00 03 F0 A5 A5
					/* Solve the problem of mirror display shadow */
					39 00 00 40 00 00 03 F0 5A 5A
					39 00 00 40 00 00 04 B0 00 4A E1
					39 00 00 40 00 00 02 E1 1F
					39 00 00 40 00 00 04 B0 00 4B E1
					39 00 00 40 00 00 0B E1 10 10 10 10 10 10 10 10 10 10
					39 00 00 40 00 00 04 B0 00 55 E1
					39 00 00 40 00 00 0B E1 08 08 08 08 08 08 08 08 08 08
					39 00 00 40 00 00 04 B0 00 6B E1
					39 00 00 40 00 00 0B E1 0C 0C 0C 0C 0C 0C 0C 0C 0C 0C
					39 00 00 40 00 00 04 B0 00 75 E1
					39 00 00 40 00 00 02 E1 FF
					39 00 00 40 00 00 02 F7 0F
					39 00 00 00 00 00 03 F0 A5 A5

					39 00 00 40 00 00 03 F0 5A 5A
					39 00 00 40 00 00 04 B0 00 8D E1
					39 00 00 40 00 00 02 E1 10
					39 00 00 00 00 00 03 F0 A5 A5
					/* display on */
					05 00 00 00 00 00 01 29
				];

				qcom,mdss-dsi-lp1-command = [
					/* AOD 30Hz */
					39 00 00 40 00 00 03 F0 5A 5A
					39 00 00 40 00 00 03 FC 5A 5A
					39 00 00 40 00 00 04 B0 00 C6 D5
					15 00 00 40 00 00 02 D5 00
					39 00 00 40 00 00 04 B0 00 DB D5
					39 00 00 40 00 00 05 D5 0B B0 0C 30
					39 00 00 40 00 00 04 B0 00 E8 D5
					15 00 00 40 00 00 02 D5 00
					39 00 00 40 00 00 04 B0 00 04 F4
					15 00 00 40 00 00 02 F4 0A
					39 00 00 40 00 00 04 B0 00 B2 E4
					39 00 00 40 00 00 03 E4 00 00
					39 00 00 40 00 00 04 B0 00 67 E4
					15 00 00 40 00 00 02 E4 22
					39 00 00 40 00 00 04 B0 00 90 E4
					39 00 00 40 00 00 03 E4 00 00
					39 00 00 40 00 00 04 B0 00 D2 E4
					39 00 00 40 00 00 11 E4 00 00 00 00 00 00 00 00 00 00 00 00 00 00 00 00
					39 00 00 40 00 00 04 B0 00 A9 E4
					15 00 00 40 00 00 02 E4 00
					15 00 00 40 00 00 02 53 24
					39 00 00 40 00 00 03 51 03 DB
					39 00 00 40 00 00 04 B0 00 F4 E4
					15 00 00 40 00 00 02 E4 22
					39 00 00 40 00 00 04 B0 00 65 E4
					39 00 00 40 00 00 06 E4 00 00 00 00 00
					15 00 00 40 00 00 02 F7 0F
					39 00 00 40 00 00 03 FC A5 A5
					39 00 00 00 00 00 03 F0 A5 A5
				];
				qcom,mdss-dsi-nolp-command = [
					/* AOD off */
					39 00 00 40 00 00 03 F0 5A 5A
					39 00 00 40 00 00 03 FC 5A 5A
					39 00 00 40 00 00 04 B0 00 04 F4
					15 00 00 40 00 00 02 F4 0A
					39 00 00 40 00 00 04 B0 00 DB D5
					39 00 00 40 00 00 05 D5 0B B0 0C 30
					39 00 00 40 00 00 04 B0 00 E8 D5
					15 00 00 40 00 00 02 D5 00
					15 00 00 40 00 00 02 53 20
					39 00 00 40 00 00 04 B0 00 A9 E4
					15 00 00 40 00 00 02 E4 00
					39 00 00 40 00 00 04 B0 00 F4 E4
					15 00 00 40 00 00 02 E4 22
					39 00 00 40 00 00 04 B0 00 65 E4
					39 00 00 40 00 00 06 E4 00 00 00 00 00
					15 00 00 40 00 00 02 F7 0F
					39 00 00 40 00 00 03 FC A5 A5
					39 00 00 00 00 00 03 F0 A5 A5
				];
				qcom,mdss-dsi-ultra-low-power-aod-on-command = [
					/* AOD 1Hz */
					39 00 00 40 00 00 03 F0 5A 5A
					39 00 00 40 00 00 03 FC 5A 5A
					39 00 00 40 00 00 04 B0 00 C6 D5
					15 00 00 40 00 00 02 D5 00
					39 00 00 40 00 00 04 B0 00 04 F4
					15 00 00 40 00 00 02 F4 0A
					39 00 00 40 00 00 04 B0 00 DB D5
					39 00 00 40 00 00 05 D5 0B B0 0C 30
					39 00 00 40 00 00 04 B0 00 E8 D5
					15 00 00 40 00 00 02 D5 00
					39 00 00 40 00 00 04 B0 00 B2 E4
					39 00 00 40 00 00 03 E4 00 74
					39 00 00 40 00 00 04 B0 00 67 E4
					15 00 00 40 00 00 02 E4 22
					39 00 00 40 00 00 04 B0 00 90 E4
					39 00 00 40 00 00 03 E4 00 00
					39 00 00 40 00 00 04 B0 00 D2 E4
					39 00 00 40 00 00 11 E4 00 00 00 74 00 74 00 74 00 74 00 74 00 74 00 74
					39 00 00 40 00 00 04 B0 00 A9 E4
					15 00 00 40 00 00 02 E4 01
					15 00 00 40 00 00 02 53 24
					39 00 00 40 00 00 04 B0 00 F4 E4
					15 00 00 40 00 00 02 E4 00
					39 00 00 40 00 00 04 B0 00 65 E4
					39 00 00 40 00 00 06 E4 22 22 22 22 22
					15 00 00 40 00 00 02 F7 0F
					39 00 00 40 00 00 03 FC A5 A5
					39 00 00 00 00 00 03 F0 A5 A5
				];
				qcom,mdss-dsi-ultra-low-power-aod-off-command = [
					/* AOD 1Hz OFF, use AOD 30Hz */
					39 00 00 40 00 00 03 F0 5A 5A
					39 00 00 40 00 00 03 FC 5A 5A
					39 00 00 40 00 00 04 B0 00 C6 D5
					15 00 00 40 00 00 02 D5 00
					39 00 00 40 00 00 04 B0 00 04 F4
					15 00 00 40 00 00 02 F4 0A
					39 00 00 40 00 00 04 B0 00 B2 E4
					39 00 00 40 00 00 03 E4 00 00
					39 00 00 40 00 00 04 B0 00 67 E4
					15 00 00 40 00 00 02 E4 22
					39 00 00 40 00 00 04 B0 00 90 E4
					39 00 00 40 00 00 03 E4 00 00
					39 00 00 40 00 00 04 B0 00 D2 E4
					39 00 00 40 00 00 11 E4 00 00 00 00 00 00 00 00 00 00 00 00 00 00 00 00
					39 00 00 40 00 00 04 B0 00 A9 E4
					15 00 00 40 00 00 02 E4 00
					15 00 00 40 00 00 02 53 24
					39 00 00 40 00 00 04 B0 00 F4 E4
					15 00 00 40 00 00 02 E4 22
					39 00 00 40 00 00 04 B0 00 65 E4
					39 00 00 40 00 00 06 E4 00 00 00 00 00
					15 00 00 40 00 00 02 F7 0F
					39 00 00 40 00 00 03 FC A5 A5
					39 00 00 00 00 00 03 F0 A5 A5
				];

				/* standard adfr */
				qcom,mdss-dsi-h-sync-skew = <0>;
				oplus,adfr-min-fps-mapping-table = <120 10 1>;
				//oplus,adfr-idle-off-min-fps = <20>;
				//18pulse
				qcom,mdss-dsi-hpwm-adfr-min-fps-0-command = [
					/* 120Hz */
					/* Level 2/3 key Enable */
					39 00 00 40 00 00 03 F0 5A 5A
					39 00 00 40 00 00 03 FC 5A 5A
					/* HOP Auto Mode OFF */
					39 00 00 40 00 00 04 B0 00 B0 E4			/* Target Freq.Setting */
					39 00 00 40 00 00 03 E4 00 00				/* BASE 120Hz(1CYC.) Low Freq. Setting, 0x00,0x00 : 120Hz */
					39 00 00 40 00 00 04 B0 00 88 E4
					39 00 00 40 00 00 05 E4 00 03 00 03			/* Insert Valid Freq.Setting */
					39 00 00 40 00 00 04 B0 00 BA E4
					39 00 00 40 00 00 11 E4 00 00 00 03 00 0B 00 0B 00 17 00 17 00 17 00 77	/* Step Delay Freq. 120-30-10-10-5-5-5-1 */
					39 00 00 40 00 00 04 B0 00 A9 E4
					15 00 00 40 00 00 02 E4 00					/* 0x00: Auto Off , 0x01: Auto On */
					/* Force Increasing OFF */
					39 00 00 40 00 00 04 B0 00 F4 E4
					15 00 00 40 00 00 02 E4 22					/* 0x00: On , 0x22: Off */
					39 00 00 40 00 00 04 B0 00 65 E4
					39 00 00 40 00 00 06 E4 00 00 00 00 00
					15 00 00 40 00 00 02 F7 0F
					/* Level 2/3 key Disable */
					39 00 00 40 00 00 03 F0 A5 A5
					39 00 00 00 00 00 03 FC A5 A5
				];
				qcom,mdss-dsi-hpwm-adfr-min-fps-1-command = [
					/* 10Hz */
					/* Level 2/3 key Enable */
					39 00 00 40 00 00 03 F0 5A 5A
					39 00 00 40 00 00 03 FC 5A 5A
					/* HOP Auto Mode ON */
					39 00 00 40 00 00 04 B0 00 B0 E4			/* Target Freq.Setting */
					39 00 00 40 00 00 03 E4 00 0B				/* BASE 120Hz(1CYC.) Low Freq. Setting, 0x00, 0x0B : 10Hz */
					39 00 00 40 00 00 04 B0 00 88 E4
					39 00 00 40 00 00 05 E4 00 03 00 03			/* Insert Valid Freq.Setting */
					39 00 00 40 00 00 04 B0 00 BA E4
					39 00 00 40 00 00 11 E4 00 00 00 03 00 0B 00 0B 00 0B 00 0B 00 0B 00 0B	/* Step Delay Freq. 120-30-10-10-10-10-10-10 */
					39 00 00 40 00 00 04 B0 00 A9 E4
					15 00 00 40 00 00 02 E4 01					/* 0x00: Auto Off , 0x01: Auto On */
					/* Force Increasing ON */
					39 00 00 40 00 00 04 B0 00 F4 E4
					15 00 00 40 00 00 02 E4 00					/* 0x00: On , 0x22: Off */
					39 00 00 40 00 00 04 B0 00 65 E4
					39 00 00 40 00 00 06 E4 22 22 22 22 22
					15 00 00 40 00 00 02 F7 0F
					/* Level 2/3 key Disable */
					39 00 00 40 00 00 03 F0 A5 A5
					39 00 00 00 00 00 03 FC A5 A5
				];
				qcom,mdss-dsi-hpwm-adfr-min-fps-2-command = [
					/* 1Hz */
					/* Level 2/3 key Enable */
					39 00 00 40 00 00 03 F0 5A 5A
					39 00 00 40 00 00 03 FC 5A 5A
					/* HOP Auto Mode ON */
					39 00 00 40 00 00 04 B0 00 B0 E4			/* Target Freq.Setting */
					39 00 00 40 00 00 03 E4 00 77				/* BASE 120Hz(1CYC.) Low Freq. Setting, 0x00,0x77 : 1Hz */
					39 00 00 40 00 00 04 B0 00 88 E4
					39 00 00 40 00 00 05 E4 00 03 00 03			/* Insert Valid Freq.Setting */
					39 00 00 40 00 00 04 B0 00 BA E4
					39 00 00 40 00 00 11 E4 00 00 00 03 00 0B 00 0B 00 17 00 17 00 17 00 77	/* Step Delay Freq. 120-30-10-10-5-5-5-1 */
					39 00 00 40 00 00 04 B0 00 A9 E4
					15 00 00 40 00 00 02 E4 01					/* 0x00: Auto Off , 0x01: Auto On */
					/* Force Increasing ON */
					39 00 00 40 00 00 04 B0 00 F4 E4
					15 00 00 40 00 00 02 E4 00					/* 0x00: On , 0x22: Off */
					39 00 00 40 00 00 04 B0 00 65 E4
					39 00 00 40 00 00 06 E4 22 22 22 22 22
					15 00 00 40 00 00 02 F7 0F
					/* Level 2/3 key Disable */
					39 00 00 40 00 00 03 F0 A5 A5
					39 00 00 00 00 00 03 FC A5 A5
				];
				//1 pulse
				qcom,mdss-dsi-bigdc-adfr-min-fps-0-command = [
					/* 120Hz */
					/* Level 2/3 key Enable */
					39 00 00 40 00 00 03 F0 5A 5A
					39 00 00 40 00 00 03 FC 5A 5A
					/* HOP Auto Mode OFF */
					39 00 00 40 00 00 04 B0 00 B0 E4			/* Target Freq.Setting */
					39 00 00 40 00 00 03 E4 00 00				/* BASE 120Hz(1CYC.) Low Freq. Setting, 0x00,0x00 : 120Hz */
					39 00 00 40 00 00 04 B0 00 88 E4
					39 00 00 40 00 00 05 E4 00 03 00 03			/* Insert Valid Freq.Setting */
					39 00 00 40 00 00 04 B0 00 BA E4
					39 00 00 40 00 00 11 E4 00 00 00 03 00 0B 00 0B 00 17 00 17 00 17 00 77	/* Step Delay Freq. 120-30-10-10-5-5-5-1 */
					39 00 00 40 00 00 04 B0 00 A9 E4
					15 00 00 40 00 00 02 E4 00					/* 0x00: Auto Off , 0x01: Auto On */
					/* Force Increasing OFF */
					39 00 00 40 00 00 04 B0 00 F4 E4
					15 00 00 40 00 00 02 E4 22					/* 0x00: On , 0x22: Off */
					39 00 00 40 00 00 04 B0 00 65 E4
					39 00 00 40 00 00 06 E4 00 00 00 00 00
					15 00 00 40 00 00 02 F7 0F
					/* Level 2/3 key Disable */
					39 00 00 40 00 00 03 F0 A5 A5
					39 00 00 00 00 00 03 FC A5 A5
				];
				qcom,mdss-dsi-bigdc-adfr-min-fps-1-command = [
					/* 10Hz */
					/* Level 2/3 key Enable */
					39 00 00 40 00 00 03 F0 5A 5A
					39 00 00 40 00 00 03 FC 5A 5A
					/* HOP Auto Mode ON */
					39 00 00 40 00 00 04 B0 00 B0 E4			/* Target Freq.Setting */
					39 00 00 40 00 00 03 E4 00 0B				/* BASE 120Hz(1CYC.) Low Freq. Setting, 0x00, 0x0B : 10Hz */
					39 00 00 40 00 00 04 B0 00 88 E4
					39 00 00 40 00 00 05 E4 00 03 00 03			/* Insert Valid Freq.Setting */
					39 00 00 40 00 00 04 B0 00 BA E4
					39 00 00 40 00 00 11 E4 00 00 00 03 00 0B 00 0B 00 0B 00 0B 00 0B 00 0B	/* Step Delay Freq. 120-30-10-10-10-10-10-10 */
					39 00 00 40 00 00 04 B0 00 A9 E4
					15 00 00 40 00 00 02 E4 01					/* 0x00: Auto Off , 0x01: Auto On */
					/* Force Increasing ON */
					39 00 00 40 00 00 04 B0 00 F4 E4
					15 00 00 40 00 00 02 E4 00					/* 0x00: On , 0x22: Off */
					39 00 00 40 00 00 04 B0 00 65 E4
					39 00 00 40 00 00 06 E4 22 22 22 22 22
					15 00 00 40 00 00 02 F7 0F
					/* Level 2/3 key Disable */
					39 00 00 40 00 00 03 F0 A5 A5
					39 00 00 00 00 00 03 FC A5 A5
				];
				qcom,mdss-dsi-bigdc-adfr-min-fps-2-command = [
					/* 1Hz */
					/* Level 2/3 key Enable */
					39 00 00 40 00 00 03 F0 5A 5A
					39 00 00 40 00 00 03 FC 5A 5A
					/* HOP Auto Mode ON */
					39 00 00 40 00 00 04 B0 00 B0 E4			/* Target Freq.Setting */
					39 00 00 40 00 00 03 E4 00 77				/* BASE 120Hz(1CYC.) Low Freq. Setting, 0x00,0x77 : 1Hz */
					39 00 00 40 00 00 04 B0 00 88 E4
					39 00 00 40 00 00 05 E4 00 03 00 03			/* Insert Valid Freq.Setting */
					39 00 00 40 00 00 04 B0 00 BA E4
					39 00 00 40 00 00 11 E4 00 00 00 03 00 0B 00 0B 00 17 00 17 00 17 00 77	/* Step Delay Freq. 120-30-10-10-5-5-5-1 */
					39 00 00 40 00 00 04 B0 00 A9 E4
					15 00 00 40 00 00 02 E4 01					/* 0x00: Auto Off , 0x01: Auto On */
					/* Force Increasing ON */
					39 00 00 40 00 00 04 B0 00 F4 E4
					15 00 00 40 00 00 02 E4 00					/* 0x00: On , 0x22: Off */
					39 00 00 40 00 00 04 B0 00 65 E4
					39 00 00 40 00 00 06 E4 22 22 22 22 22
					15 00 00 40 00 00 02 F7 0F
					/* Level 2/3 key Disable */
					39 00 00 40 00 00 03 F0 A5 A5
					39 00 00 00 00 00 03 FC A5 A5
				];

				qcom,mdss-dsi-pwm-state-l1tol3-command = [
					39 00 00 40 00 00 03 F0 5A 5A
					39 00 00 40 00 00 04 B0 00 D7 BF
					15 00 00 40 00 00 02 BF 01
					39 00 00 40 00 00 04 B0 00 9A C0
					39 00 00 40 00 00 61 C0 00 04 08 10 18 20 28 38 40 50 60 70 80 90 A0 B0 C0 D0 E0 E8 F0 F8 FC FE FF FF FF FF FF FF FF FF 00 04 08 10 18 20 28 38 40 50 60 70 80 90 A0 B0 C0 D0 E0 E8 F0 F8 FC FE FF FF FF FF FF FF FF FF 00 04 08 10 18 20 28 38 40 50 60 70 80 90 A0 B0 C0 D0 E0 E8 F0 F8 FC FE FF FF FF FF FF FF FF FF
					39 00 00 40 00 00 04 B0 00 D8 BF
					39 00 00 40 00 00 27 BF 00 00 3F EC 3F CE 3F CE 3F 9C 3F 9C 3F B0 3F 9C 3F D8 00 58 00 58 00 48 00 58 00 48 00 58 00 58 00 40 00 58 00 58
					39 00 00 40 00 00 1B C0 00 58 00 58 00 58 00 58 00 58 00 58 00 58 00 58 00 58 00 58 00 58 00 58 00 58
					39 00 00 40 00 00 04 B0 00 1A C0
					39 00 00 40 00 00 41 C0 00 00 3F EC 3F CE 3F CE 3F 9C 3F 9C 3F B0 3F 9C 3F D8 00 58 00 58 00 48 00 58 00 48 00 58 00 58 00 40 00 58 00 58 00 58 00 58 00 58 00 58 00 58 00 58 00 58 00 58 00 58 00 58 00 58 00 58 00 58
					39 00 00 40 00 00 04 B0 00 5A C0
					39 00 00 40 00 00 41 C0 00 00 3F EC 3F CE 3F CE 3F 9C 3F 9C 3F B0 3F 9C 3F D8 00 58 00 58 00 48 00 58 00 48 00 58 00 58 00 40 00 58 00 58 00 58 00 58 00 58 00 58 00 58 00 58 00 58 00 58 00 58 00 58 00 58 00 58 00 58
					15 00 00 40 00 00 02 F7 0F
					39 00 00 00 00 00 03 F0 A5 A5
				];
				qcom,mdss-dsi-pwm-state-l3tol1-command = [
					39 00 00 40 00 00 03 F0 5A 5A
					39 00 00 40 00 00 04 B0 00 D7 BF
					15 00 00 40 00 00 02 BF 01
					39 00 00 40 00 00 04 B0 00 9A C0
					39 00 00 40 00 00 61 C0 00 04 08 10 18 20 28 38 48 58 68 78 88 98 A8 B8 C8 D8 E8 EC FC FE FF FF FF FF FF FF FF FF FF FF 00 04 08 10 18 20 28 38 48 58 68 78 88 98 A8 B8 C8 D8 E8 EC FC FE FF FF FF FF FF FF FF FF FF FF 00 04 08 10 18 20 28 38 48 58 68 78 88 98 A8 B8 C8 D8 E8 EC FC FE FF FF FF FF FF FF FF FF FF FF
					39 00 00 40 00 00 04 B0 00 D8 BF
					39 00 00 40 00 00 27 BF 00 00 00 01 00 01 00 01 00 01 00 01 00 01 3F EC 3F F6 3F DD 3F DD 3F C9 3F E4 3F E4 3F C4 3F CE 3F CE 3F CE 3F CE
					39 00 00 40 00 00 1B C0 3F CE 3F CE 3F CE 3F CE 3F CE 3F CE 3F CE 3F CE 3F CE 3F CE 3F CE 3F CE 3F CE
					39 00 00 40 00 00 04 B0 00 1A C0
					39 00 00 40 00 00 41 C0 00 00 00 01 00 01 00 01 00 01 00 01 00 01 3F EC 3F F6 3F DD 3F DD 3F C9 3F E4 3F E4 3F C4 3F CE 3F CE 3F CE 3F CE 3F CE 3F CE 3F CE 3F CE 3F CE 3F CE 3F CE 3F CE 3F CE 3F CE 3F CE 3F CE 3F CE
					39 00 00 40 00 00 04 B0 00 5A C0
					39 00 00 40 00 00 41 C0 00 00 00 01 00 01 00 01 00 01 00 01 00 01 3F EC 3F F6 3F DD 3F DD 3F C9 3F E4 3F E4 3F C4 3F E4 3F E4 3F E4 3F E4 3F E4 3F E4 3F E4 3F E4 3F E4 3F E4 3F E4 3F E4 3F E4 3F E4 3F E4 3F E4 3F E4
					15 00 00 40 00 00 02 F7 0F
					39 00 00 00 00 00 03 F0 A5 A5
				];
				qcom,mdss-dsi-pwm-dbv-threshold-extend-command = [
					39 00 00 40 00 00 03 F0 5A 5A
					39 00 00 40 00 00 04 B0 00 D7 BF
					15 00 00 40 00 00 02 BF 00
					15 00 00 40 00 00 02 F7 0F
					39 00 00 00 00 00 03 F0 A5 A5
				];

				qcom,mdss-dsi-timming-pwm-switch-onepulse-command = [
					/* Level 2/3 key Enable */
					39 00 00 40 00 00 03 F0 5A 5A
					39 00 00 40 00 00 03 FC 5A 5A
					/* Sync_TE Setting: Fixed TE */
					39 00 00 40 00 00 04 B0 00 C6 D5
					39 00 00 40 00 00 02 D5 00
					39 00 00 40 00 00 04 B0 00 04 F4
					15 00 00 40 00 00 02 F4 0A
					39 00 00 40 00 00 04 B0 00 DB D5
					39 00 00 40 00 00 05 D5 0B B0 0C 30			/* 0x0B : Fixed TE */
					39 00 00 40 00 00 04 B0 00 E8 D5
					15 00 00 40 00 00 02 D5 00					/* 0x00 : 120Hz */
					/* Frequency Setting */
					39 00 00 40 00 00 03 60 00 00				/* 0x08 : 120Hz(1) */
					/* Insert Valid Freq.Setting */
					39 00 00 40 00 00 04 B0 00 88 E4
					39 00 00 40 00 00 05 E4 00 03 00 03
					/* HOP Auto Mode OFF */
					39 00 00 40 00 00 04 B0 00 A9 E4
					15 00 00 40 00 00 02 E4 00					/* 0x00: Auto Off , 0x01: Auto On */
					/* Force Increasing OFF */
					39 00 00 40 00 00 04 B0 00 F4 E4
					15 00 00 40 00 00 02 E4 22					/* 0x00: On , 0x22: Off */
					39 00 00 40 00 00 04 B0 00 65 E4
					39 00 00 40 00 00 06 E4 00 00 00 00 00
					15 00 00 40 00 00 02 F7 0F
					/* Level 2/3 key Disable */
					39 00 00 40 00 00 03 F0 A5 A5
					39 00 00 00 00 00 03 FC A5 A5
				];
				qcom,mdss-dsi-pwm-switch-mode0-command = [
					/* Level 2/3 key Enable */
					39 00 00 40 00 00 03 F0 5A 5A
					39 00 00 40 00 00 03 FC 5A 5A
					/* Sync_TE Setting: Fixed TE */
					39 00 00 40 00 00 04 B0 00 C6 D5
					39 00 00 40 00 00 02 D5 00
					39 00 00 40 00 00 04 B0 00 04 F4
					15 00 00 40 00 00 02 F4 0A
					39 00 00 40 00 00 04 B0 00 DB D5
					39 00 00 40 00 00 05 D5 0B B0 0C 30			/* 0x0B : Fixed TE */
					39 00 00 40 00 00 04 B0 00 E8 D5
					15 00 00 40 00 00 02 D5 00					/* 0x00 : 120Hz */
					/* Frequency Setting */
					39 00 00 40 00 00 03 60 00 08				/* 0x08 : 120Hz(1/18cyc) */
					/* HOP Auto Mode OFF */
					39 00 00 40 00 00 04 B0 00 A9 E4
					15 00 00 40 00 00 02 E4 00					/* 0x00: Auto Off , 0x01: Auto On */
					/* Force Increasing OFF */
					39 00 00 40 00 00 04 B0 00 F4 E4
					15 00 00 40 00 00 02 E4 22					/* 0x00: On , 0x22: Off */
					39 00 00 40 00 00 04 B0 00 65 E4
					39 00 00 40 00 00 06 E4 00 00 00 00 00
					15 00 00 40 00 00 02 F7 0F
					/* Level 2/3 key Disable */
					39 00 00 40 00 00 03 F0 A5 A5
					39 00 00 00 00 00 03 FC A5 A5
				];
				qcom,mdss-dsi-pwm-switch-mode1-command = [
					/* Level 2/3 key Enable */
					39 00 00 40 00 00 03 F0 5A 5A
					39 00 00 40 00 00 03 FC 5A 5A
					/* Sync_TE Setting: Fixed TE */
					39 00 00 40 00 00 04 B0 00 C6 D5
					39 00 00 40 00 00 02 D5 00
					39 00 00 40 00 00 04 B0 00 04 F4
					15 00 00 40 00 00 02 F4 0A
					39 00 00 40 00 00 04 B0 00 DB D5
					39 00 00 40 00 00 05 D5 0B B0 0C 30			/* 0x0B : Fixed TE */
					39 00 00 40 00 00 04 B0 00 E8 D5
					15 00 00 40 00 00 02 D5 00					/* 0x00 : 120Hz */
					/* Frequency Setting */
					39 00 00 40 00 00 03 60 00 00				/* 0x08 : 120Hz(1) */
					/* HOP Auto Mode OFF */
					39 00 00 40 00 00 04 B0 00 A9 E4
					15 00 00 40 00 00 02 E4 00					/* 0x00: Auto Off , 0x01: Auto On */
					/* Force Increasing OFF */
					39 00 00 40 00 00 04 B0 00 F4 E4
					15 00 00 40 00 00 02 E4 22					/* 0x00: On , 0x22: Off */
					39 00 00 40 00 00 04 B0 00 65 E4
					39 00 00 40 00 00 06 E4 00 00 00 00 00
					15 00 00 40 00 00 02 F7 0F
					/* Level 2/3 key Disable */
					39 00 00 40 00 00 03 F0 A5 A5
					39 00 00 00 00 00 03 FC A5 A5
				];
				qcom,mdss-dsi-pwm-switch-mode1-panel-on-command = [
					/* Level 2/3 key Enable */
					39 00 00 40 00 00 03 F0 5A 5A
					39 00 00 40 00 00 03 FC 5A 5A
					/* Sync_TE Setting: Fixed TE */
					39 00 00 40 00 00 04 B0 00 C6 D5
					39 00 00 40 00 00 02 D5 00
					39 00 00 40 00 00 04 B0 00 04 F4
					15 00 00 40 00 00 02 F4 0A
					39 00 00 40 00 00 04 B0 00 DB D5
					39 00 00 40 00 00 05 D5 0B B0 0C 30			/* 0x0B : Fixed TE */
					39 00 00 40 00 00 04 B0 00 E8 D5
					15 00 00 40 00 00 02 D5 00					/* 0x00 : 120Hz */
					/* Frequency Setting */
					39 00 00 40 00 00 03 60 00 00				/* 0x08 : 120Hz(1) */
					/* HOP Auto Mode OFF */
					39 00 00 40 00 00 04 B0 00 A9 E4
					15 00 00 40 00 00 02 E4 00					/* 0x00: Auto Off , 0x01: Auto On */
					/* Force Increasing OFF */
					39 00 00 40 00 00 04 B0 00 F4 E4
					15 00 00 40 00 00 02 E4 22					/* 0x00: On , 0x22: Off */
					39 00 00 40 00 00 04 B0 00 65 E4
					39 00 00 40 00 00 06 E4 00 00 00 00 00
					15 00 00 40 00 00 02 F7 0F
					/* Level 2/3 key Disable */
					39 00 00 40 00 00 03 F0 A5 A5
					39 00 00 00 00 00 03 FC A5 A5
				];

			};
			timing@oa_fhd_120{
				#include "dsi-panel-AB849-P-1-A0022-common.dtsi"
				//qcom,mdss-mdp-transfer-time-us = <6000>;
				#include "dsi-panel-AB849-P-1-A0022-loading-effect.dtsi"
				cell-index = <2>;
				qcom,mdss-dsi-panel-framerate = <120>;
				qcom,mdss-dsi-panel-clockrate = <1113600000>;
				qcom,mdss-dsi-panel-width = <1264>;
				qcom,mdss-dsi-panel-height = <2780>;
				qcom,dsi-mode-te-width-us = <290>;

				qcom,mdss-dsi-h-front-porch = <64>;
				qcom,mdss-dsi-h-back-porch = <50>;
				qcom,mdss-dsi-h-pulse-width = <8>;
				qcom,mdss-dsi-h-sync-pulse = <0>;
				qcom,mdss-dsi-v-back-porch = <8>;
				qcom,mdss-dsi-v-front-porch = <2>;
				qcom,mdss-dsi-v-pulse-width = <2>;

				qcom,mdss-dsi-timing-switch-command = [
					/* Level 2/3 key Enable */
					39 00 00 40 00 00 03 F0 5A 5A
					39 00 00 40 00 00 03 FC 5A 5A
					/* Sync_TE Setting: Fixed TE */
					39 00 00 40 00 00 04 B0 00 C6 D5
					39 00 00 40 00 00 02 D5 00
					39 00 00 40 00 00 04 B0 00 04 F4
					15 00 00 40 00 00 02 F4 0A
					39 00 00 40 00 00 04 B0 00 DB D5
					39 00 00 40 00 00 05 D5 00 B0 0C 30			/* 0x00 : Changeable TE */
					39 00 00 40 00 00 04 B0 00 E8 D5
					15 00 00 40 00 00 02 D5 00					/* 0x00 : 120Hz */
					/* Frequency Setting */
					39 00 00 40 00 00 03 60 00 08				/* 0x08 : 120Hz(1cyc) */
					/* Insert Valid Freq.Setting */
					39 00 00 40 00 00 04 B0 00 88 E4
					39 00 00 40 00 00 05 E4 00 03 00 03
					/* HOP Auto Mode OFF */
					39 00 00 40 00 00 04 B0 00 A9 E4
					15 00 00 40 00 00 02 E4 00					/* 0x00: Auto Off , 0x01: Auto On */
					/* Force Increasing OFF */
					39 00 00 40 00 00 04 B0 00 F4 E4
					15 00 00 40 00 00 02 E4 22					/* 0x00: On , 0x22: Off */
					39 00 00 40 00 00 04 B0 00 65 E4
					39 00 00 40 00 00 06 E4 00 00 00 00 00
					15 00 00 40 00 00 02 F7 0F
					/* Level 2/3 key Disable */
					39 00 00 40 00 00 03 F0 A5 A5
					39 00 00 00 00 00 03 FC A5 A5
				];

				qcom,mdss-dsi-on-command = [
					/* DSC V1.2 Setting 10bit (1264 x 2780, height 139) */
					39 00 00 40 00 00 81 9E 12 00 00 AB 30 80 0A DC 04 F0 00 8B 02 78 02 78 02 00 02 8C 00 20 0B 55 00 08 00 0F 00 DF 00 A1 18 00 11 00 07 10 20 00 06 0F 0F 33 0E 1C 2A 38 46 54 62 69 70 77 79 7B 7D 7E 02 02 22 00 2A 40 2A BE 3A FC 3A FA 3A F8 3B 38 3B 78 3B B6 4B B6 4B F4 4B F4 6C 34 84 74 00 00 00 00 00 00 00 00 00 00 00 00 00 00 00 00 00 00 00 00 00 00 00 00 00 00 00 00 00 00 00 00 00 00 00 00 00 00 00 00
					15 00 00 00 00 00 02 9D 01

					/* Sleep Out(11h) */
					05 00 00 00 66 00 01 11

					/* Common Setting */
					/* TE(Vsync) ON */
					15 00 00 40 00 00 02 35 00
					/* CASET/PASET Setting */
					39 00 00 40 00 00 05 2A 00 00 04 EF
					39 00 00 40 00 00 05 2B 00 00 0A DB
					/* TSP Sync Enable */
					39 00 00 40 00 00 03 F0 5A 5A
					39 00 00 40 00 00 04 B0 00 D8 D5
					15 00 00 40 00 00 02 D5 03
					39 00 00 40 00 00 04 B0 00 C0 D5
					39 00 00 40 00 00 03 D5 06 10
					15 00 00 40 00 00 02 F7 0F
					39 00 00 00 00 00 03 F0 A5 A5
					/* Edge Dimming Code */
					39 00 00 40 00 00 03 F0 5A 5A
					39 00 00 40 00 00 04 B0 00 02 B1
					39 00 00 40 00 00 05 B1 BF BF CF FF
					39 00 00 00 00 00 03 F0 A5 A5
					/* SPR Code */
					39 00 00 40 00 00 03 F0 5A 5A
					39 00 00 40 00 00 04 B0 00 06 B1
					15 00 00 40 00 00 02 B1 50
					39 00 00 40 00 00 03 F0 A5 A5
					/* FFC Code @556.8Mhz, OSC 138.6MHz */
					39 00 00 40 00 00 03 F0 5A 5A
					39 00 00 40 00 00 5B E2 00 80 22 00 00 00 00 00 00 00 00 00 01 90 E4 00 00 00 11 80 00 00 11 80 00 00 11 80 00 00 11 80 00 02 00 14 00 00 0B B8 00 0A 00 A6 00 00 00 00 00 00 00 00 04 04 00 00 00 00 00 00 00 03 00 00 00 04 00 00 27 10 FF FF D8 F0 10 00 00 00 0A 01 04 06 00 00 00 00 00 00 01 00
					39 00 00 40 00 00 02 F7 0F
					39 00 00 00 00 00 03 F0 A5 A5
					/* AOD Sync Setting */
					39 00 00 40 00 00 03 F0 5A 5A
					39 00 00 40 00 00 04 B0 00 92 D4
					15 00 00 40 00 00 02 D4 00
					15 00 00 40 00 00 02 F7 0F
					39 00 00 40 00 00 03 F0 A5 A5
					/* AOD Setting In HOP Mode */
					39 00 00 40 00 00 03 F0 5A 5A
					39 00 00 40 00 00 04 B0 00 C0 EE
					39 00 00 40 00 00 11 EE 05 00 03 00 07 00 03 00 01 00 03 00 03 00 03 00
					15 00 00 40 00 00 02 F7 0F
					39 00 00 00 00 00 03 F0 A5 A5

					/* Brightness Control */
					/* Dimming Setting */
					39 00 00 40 00 00 03 F0 5A 5A
					15 00 00 40 00 00 02 53 20
					39 00 00 40 00 00 03 51 00 00
					39 00 00 40 00 00 03 F0 A5 A5
					/* Level 2/3 key Enable */
					39 00 00 40 00 00 03 F0 5A 5A
					39 00 00 40 00 00 03 FC 5A 5A
					/* Sync_TE Setting: Fixed TE */
					39 00 00 40 00 00 04 B0 00 C6 D5
					39 00 00 40 00 00 02 D5 00
					39 00 00 40 00 00 04 B0 00 04 F4
					15 00 00 40 00 00 02 F4 0A
					39 00 00 40 00 00 04 B0 00 DB D5
					39 00 00 40 00 00 05 D5 0B B0 0C 30			/* 0x0B : Fixed TE */
					39 00 00 40 00 00 04 B0 00 E8 D5
					15 00 00 40 00 00 02 D5 00					/* 0x00 : 120Hz */
					/* Frequency Setting */
					39 00 00 40 00 00 03 60 00 08				/* 0x08 : 120Hz(1cyc) */
					/* Insert Valid Freq.Setting */
					39 00 00 40 00 00 04 B0 00 88 E4
					39 00 00 40 00 00 05 E4 00 03 00 03
					/* HOP Auto Mode OFF */
					39 00 00 40 00 00 04 B0 00 A9 E4
					15 00 00 40 00 00 02 E4 00					/* 0x00: Auto Off , 0x01: Auto On */
					/* Force Increasing OFF */
					39 00 00 40 00 00 04 B0 00 F4 E4
					15 00 00 40 00 00 02 E4 22					/* 0x00: On , 0x22: Off */
					39 00 00 40 00 00 04 B0 00 65 E4
					39 00 00 40 00 00 06 E4 00 00 00 00 00
					15 00 00 40 00 00 02 F7 0F
					/* Level 2/3 key Disable */
					39 00 00 40 00 00 03 F0 A5 A5
					39 00 00 00 00 00 03 FC A5 A5

					/* DBV DIMMING */
					39 00 00 40 00 00 03 F0 5A 5A
					39 00 00 40 00 00 04 B0 00 65 B2
					39 00 00 40 00 00 06 B2 41 C5 1D 41 F1
					39 00 00 40 00 00 04 B0 00 B7 B2
					39 00 00 40 00 00 05 B2 01 5C 01 E8
					39 00 00 40 00 00 04 B0 00 79 B3
					15 00 00 40 00 00 02 B3 06
					39 00 00 00 00 00 03 F0 A5 A5
					/* Laoding On 110% */
					39 00 00 40 00 00 03 F0 5A 5A
					39 00 00 40 00 00 04 B0 00 02 C5
					39 00 00 40 00 00 02 C5 27
					39 00 00 40 00 00 04 B0 00 1B B1
					39 00 00 40 00 00 0F B1 72 92 2B 6D 80 CE A5 D6 AB FF 10 00 00 01
					39 00 00 40 00 00 04 B0 00 20 B1
					39 00 00 40 00 00 05 B1 73 5C D6 AB
					39 00 00 40 00 00 02 F7 0F
					39 00 00 40 00 00 03 F0 A5 A5
					/* PMIC transition period W/A */
					39 00 00 40 00 00 03 F0 5A 5A
					39 00 00 40 00 00 04 B0 00 94 D4
					39 00 00 40 00 00 03 D4 11 00
					39 00 00 40 00 00 02 F7 0F
					39 00 00 00 00 00 03 F0 A5 A5
					/* Solve the problem of mirror display shadow */
					39 00 00 40 00 00 03 F0 5A 5A
					39 00 00 40 00 00 04 B0 00 4A E1
					39 00 00 40 00 00 02 E1 1F
					39 00 00 40 00 00 04 B0 00 4B E1
					39 00 00 40 00 00 0B E1 10 10 10 10 10 10 10 10 10 10
					39 00 00 40 00 00 04 B0 00 55 E1
					39 00 00 40 00 00 0B E1 08 08 08 08 08 08 08 08 08 08
					39 00 00 40 00 00 04 B0 00 6B E1
					39 00 00 40 00 00 0B E1 0C 0C 0C 0C 0C 0C 0C 0C 0C 0C
					39 00 00 40 00 00 04 B0 00 75 E1
					39 00 00 40 00 00 02 E1 FF
					39 00 00 40 00 00 02 F7 0F
					39 00 00 00 00 00 03 F0 A5 A5

					39 00 00 40 00 00 03 F0 5A 5A
					39 00 00 40 00 00 04 B0 00 8D E1
					39 00 00 40 00 00 02 E1 10
					39 00 00 00 00 00 03 F0 A5 A5
					/* display on */
					05 00 00 00 00 00 01 29
				];

				qcom,mdss-dsi-lp1-command = [
					/* AOD 30Hz */
					39 00 00 40 00 00 03 F0 5A 5A
					39 00 00 40 00 00 03 FC 5A 5A
					39 00 00 40 00 00 04 B0 00 C6 D5
					15 00 00 40 00 00 02 D5 00
					39 00 00 40 00 00 04 B0 00 DB D5
					39 00 00 40 00 00 05 D5 0B B0 0C 30
					39 00 00 40 00 00 04 B0 00 E8 D5
					15 00 00 40 00 00 02 D5 00
					39 00 00 40 00 00 04 B0 00 04 F4
					15 00 00 40 00 00 02 F4 0A
					39 00 00 40 00 00 04 B0 00 B2 E4
					39 00 00 40 00 00 03 E4 00 00
					39 00 00 40 00 00 04 B0 00 67 E4
					15 00 00 40 00 00 02 E4 22
					39 00 00 40 00 00 04 B0 00 90 E4
					39 00 00 40 00 00 03 E4 00 00
					39 00 00 40 00 00 04 B0 00 D2 E4
					39 00 00 40 00 00 11 E4 00 00 00 00 00 00 00 00 00 00 00 00 00 00 00 00
					39 00 00 40 00 00 04 B0 00 A9 E4
					15 00 00 40 00 00 02 E4 00
					15 00 00 40 00 00 02 53 24
					39 00 00 40 00 00 03 51 03 DB
					39 00 00 40 00 00 04 B0 00 F4 E4
					15 00 00 40 00 00 02 E4 22
					39 00 00 40 00 00 04 B0 00 65 E4
					39 00 00 40 00 00 06 E4 00 00 00 00 00
					15 00 00 40 00 00 02 F7 0F
					39 00 00 40 00 00 03 FC A5 A5
					39 00 00 00 00 00 03 F0 A5 A5
				];
				qcom,mdss-dsi-nolp-command = [
					/* AOD off */
					39 00 00 40 00 00 03 F0 5A 5A
					39 00 00 40 00 00 03 FC 5A 5A
					39 00 00 40 00 00 04 B0 00 04 F4
					15 00 00 40 00 00 02 F4 0A
					39 00 00 40 00 00 04 B0 00 DB D5
					39 00 00 40 00 00 05 D5 0B B0 0C 30
					39 00 00 40 00 00 04 B0 00 E8 D5
					15 00 00 40 00 00 02 D5 00
					15 00 00 40 00 00 02 53 20
					39 00 00 40 00 00 04 B0 00 A9 E4
					15 00 00 40 00 00 02 E4 00
					39 00 00 40 00 00 04 B0 00 F4 E4
					15 00 00 40 00 00 02 E4 22
					39 00 00 40 00 00 04 B0 00 65 E4
					39 00 00 40 00 00 06 E4 00 00 00 00 00
					15 00 00 40 00 00 02 F7 0F
					39 00 00 40 00 00 03 FC A5 A5
					39 00 00 00 00 00 03 F0 A5 A5
				];
				qcom,mdss-dsi-ultra-low-power-aod-on-command = [
					/* AOD 1Hz */
					39 00 00 40 00 00 03 F0 5A 5A
					39 00 00 40 00 00 03 FC 5A 5A
					39 00 00 40 00 00 04 B0 00 C6 D5
					15 00 00 40 00 00 02 D5 00
					39 00 00 40 00 00 04 B0 00 04 F4
					15 00 00 40 00 00 02 F4 0A
					39 00 00 40 00 00 04 B0 00 DB D5
					39 00 00 40 00 00 05 D5 0B B0 0C 30
					39 00 00 40 00 00 04 B0 00 E8 D5
					15 00 00 40 00 00 02 D5 00
					39 00 00 40 00 00 04 B0 00 B2 E4
					39 00 00 40 00 00 03 E4 00 74
					39 00 00 40 00 00 04 B0 00 67 E4
					15 00 00 40 00 00 02 E4 22
					39 00 00 40 00 00 04 B0 00 90 E4
					39 00 00 40 00 00 03 E4 00 00
					39 00 00 40 00 00 04 B0 00 D2 E4
					39 00 00 40 00 00 11 E4 00 00 00 74 00 74 00 74 00 74 00 74 00 74 00 74
					39 00 00 40 00 00 04 B0 00 A9 E4
					15 00 00 40 00 00 02 E4 01
					15 00 00 40 00 00 02 53 24
					39 00 00 40 00 00 04 B0 00 F4 E4
					15 00 00 40 00 00 02 E4 00
					39 00 00 40 00 00 04 B0 00 65 E4
					39 00 00 40 00 00 06 E4 22 22 22 22 22
					15 00 00 40 00 00 02 F7 0F
					39 00 00 40 00 00 03 FC A5 A5
					39 00 00 00 00 00 03 F0 A5 A5
				];
				qcom,mdss-dsi-ultra-low-power-aod-off-command = [
					/* AOD 1Hz OFF, use AOD 30Hz */
					39 00 00 40 00 00 03 F0 5A 5A
					39 00 00 40 00 00 03 FC 5A 5A
					39 00 00 40 00 00 04 B0 00 C6 D5
					15 00 00 40 00 00 02 D5 00
					39 00 00 40 00 00 04 B0 00 04 F4
					15 00 00 40 00 00 02 F4 0A
					39 00 00 40 00 00 04 B0 00 B2 E4
					39 00 00 40 00 00 03 E4 00 00
					39 00 00 40 00 00 04 B0 00 67 E4
					15 00 00 40 00 00 02 E4 22
					39 00 00 40 00 00 04 B0 00 90 E4
					39 00 00 40 00 00 03 E4 00 00
					39 00 00 40 00 00 04 B0 00 D2 E4
					39 00 00 40 00 00 11 E4 00 00 00 00 00 00 00 00 00 00 00 00 00 00 00 00
					39 00 00 40 00 00 04 B0 00 A9 E4
					15 00 00 40 00 00 02 E4 00
					15 00 00 40 00 00 02 53 24
					39 00 00 40 00 00 04 B0 00 F4 E4
					15 00 00 40 00 00 02 E4 22
					39 00 00 40 00 00 04 B0 00 65 E4
					39 00 00 40 00 00 06 E4 00 00 00 00 00
					15 00 00 40 00 00 02 F7 0F
					39 00 00 40 00 00 03 FC A5 A5
					39 00 00 00 00 00 03 F0 A5 A5
				];

				/* standard adfr */
				qcom,mdss-dsi-h-sync-skew = <2>;
				oplus,adfr-min-fps-mapping-table = <120 30>;
				//oplus,adfr-idle-off-min-fps = <20>;
				qcom,mdss-dsi-qsync-off-commands = [

				];
				//18 pulse
				qcom,mdss-dsi-hpwm-adfr-min-fps-0-command = [
					/* 120Hz */
					/* Level 2/3 key Enable */
					39 00 00 40 00 00 03 F0 5A 5A
					39 00 00 40 00 00 03 FC 5A 5A
					/* HOP Auto Mode */
					39 00 00 40 00 00 04 B0 00 B0 E4			/* Target Freq.Setting */
					39 00 00 40 00 00 03 E4 00 00				/* BASE 120Hz(1CYC.) Low Freq. Setting, 0x00,0x00 : 120Hz */
					39 00 00 40 00 00 04 B0 00 88 E4
					39 00 00 40 00 00 05 E4 00 03 00 03			/* Insert Valid Freq.Setting */
					39 00 00 40 00 00 04 B0 00 BA E4
					39 00 00 40 00 00 11 E4 00 00 00 00 00 00 00 00 00 00 00 00 00 00 00 00	/* Step Delay Freq. ALL 120 */
					39 00 00 40 00 00 04 B0 00 A9 E4
					15 00 00 40 00 00 02 E4 01					/* 0x00: Auto Off , 0x01: Auto On */
					/* Force Increasing OFF */
					39 00 00 40 00 00 04 B0 00 F4 E4
					15 00 00 40 00 00 02 E4 00					/* 0x00: On , 0x22: Off */
					39 00 00 40 00 00 04 B0 00 65 E4
					39 00 00 40 00 00 06 E4 00 00 00 00 00
					15 00 00 40 00 00 02 F7 0F
					/* Level 2/3 key Disable */
					39 00 00 40 00 00 03 F0 A5 A5
					39 00 00 00 00 00 03 FC A5 A5
				];
				qcom,mdss-dsi-hpwm-adfr-min-fps-1-command = [
					/* 30Hz */
					/* Level 2/3 key Enable */
					39 00 00 40 00 00 03 F0 5A 5A
					39 00 00 40 00 00 03 FC 5A 5A
					/* HOP Auto Mode ON */
					39 00 00 40 00 00 04 B0 00 B0 E4			/* Target Freq.Setting */
					39 00 00 40 00 00 03 E4 00 03				/* BASE 120Hz(1CYC.) Low Freq. Setting, 0x00,0x03 : 30Hz */
					39 00 00 40 00 00 04 B0 00 88 E4
					39 00 00 40 00 00 05 E4 00 03 00 03			/* Insert Valid Freq.Setting */
					39 00 00 40 00 00 04 B0 00 BA E4
					39 00 00 40 00 00 11 E4 00 03 00 03 00 03 00 03 00 03 00 03 00 03 00 03	/* Step Delay Freq. 120-30 */
					39 00 00 40 00 00 04 B0 00 A9 E4
					15 00 00 40 00 00 02 E4 01					/* 0x00: Auto Off , 0x01: Auto On */
					/* Force Increasing ON */
					39 00 00 40 00 00 04 B0 00 F4 E4
					15 00 00 40 00 00 02 E4 00					/* 0x00: On , 0x22: Off */
					39 00 00 40 00 00 04 B0 00 65 E4
					39 00 00 40 00 00 06 E4 00 00 00 00 00
					15 00 00 40 00 00 02 F7 0F
					/* Level 2/3 key Disable */
					39 00 00 40 00 00 03 F0 A5 A5
					39 00 00 00 00 00 03 FC A5 A5
				];
				qcom,mdss-dsi-bigdc-adfr-min-fps-0-command = [
					/* 120Hz */
					/* Level 2/3 key Enable */
					39 00 00 40 00 00 03 F0 5A 5A
					39 00 00 40 00 00 03 FC 5A 5A
					/* HOP Auto Mode */
					39 00 00 40 00 00 04 B0 00 B0 E4			/* Target Freq.Setting */
					39 00 00 40 00 00 03 E4 00 00				/* BASE 120Hz(1CYC.) Low Freq. Setting, 0x00,0x00 : 120Hz */
					39 00 00 40 00 00 04 B0 00 88 E4
					39 00 00 40 00 00 05 E4 00 03 00 03			/* Insert Valid Freq.Setting */
					39 00 00 40 00 00 04 B0 00 BA E4
					39 00 00 40 00 00 11 E4 00 00 00 00 00 00 00 00 00 00 00 00 00 00 00 00	/* Step Delay Freq. ALL 120 */
					39 00 00 40 00 00 04 B0 00 A9 E4
					15 00 00 40 00 00 02 E4 01					/* 0x00: Auto Off , 0x01: Auto On */
					/* Force Increasing OFF */
					39 00 00 40 00 00 04 B0 00 F4 E4
					15 00 00 40 00 00 02 E4 00					/* 0x00: On , 0x22: Off */
					39 00 00 40 00 00 04 B0 00 65 E4
					39 00 00 40 00 00 06 E4 00 00 00 00 00
					15 00 00 40 00 00 02 F7 0F
					/* Level 2/3 key Disable */
					39 00 00 40 00 00 03 F0 A5 A5
					39 00 00 00 00 00 03 FC A5 A5
				];
				qcom,mdss-dsi-bigdc-adfr-min-fps-1-command = [
					/* 30Hz */
					/* Level 2/3 key Enable */
					39 00 00 40 00 00 03 F0 5A 5A
					39 00 00 40 00 00 03 FC 5A 5A
					/* HOP Auto Mode ON */
					39 00 00 40 00 00 04 B0 00 B0 E4			/* Target Freq.Setting */
					39 00 00 40 00 00 03 E4 00 03				/* BASE 120Hz(1CYC.) Low Freq. Setting, 0x00,0x03 : 30Hz */
					39 00 00 40 00 00 04 B0 00 88 E4
					39 00 00 40 00 00 05 E4 00 03 00 03			/* Insert Valid Freq.Setting */
					39 00 00 40 00 00 04 B0 00 BA E4
					39 00 00 40 00 00 11 E4 00 03 00 03 00 03 00 03 00 03 00 03 00 03 00 03	/* Step Delay Freq. 120-30 */
					39 00 00 40 00 00 04 B0 00 A9 E4
					15 00 00 40 00 00 02 E4 01					/* 0x00: Auto Off , 0x01: Auto On */
					/* Force Increasing ON */
					39 00 00 40 00 00 04 B0 00 F4 E4
					15 00 00 40 00 00 02 E4 00					/* 0x00: On , 0x22: Off */
					39 00 00 40 00 00 04 B0 00 65 E4
					39 00 00 40 00 00 06 E4 00 00 00 00 00
					15 00 00 40 00 00 02 F7 0F
					/* Level 2/3 key Disable */
					39 00 00 40 00 00 03 F0 A5 A5
					39 00 00 00 00 00 03 FC A5 A5
				];

				qcom,mdss-dsi-pwm-state-l1tol3-command = [
					39 00 00 40 00 00 03 F0 5A 5A
					39 00 00 40 00 00 04 B0 00 D7 BF
					15 00 00 40 00 00 02 BF 01
					39 00 00 40 00 00 04 B0 00 9A C0
					39 00 00 40 00 00 61 C0 00 04 08 10 18 20 28 38 40 50 60 70 80 90 A0 B0 C0 D0 E0 E8 F0 F8 FC FE FF FF FF FF FF FF FF FF 00 04 08 10 18 20 28 38 40 50 60 70 80 90 A0 B0 C0 D0 E0 E8 F0 F8 FC FE FF FF FF FF FF FF FF FF 00 04 08 10 18 20 28 38 40 50 60 70 80 90 A0 B0 C0 D0 E0 E8 F0 F8 FC FE FF FF FF FF FF FF FF FF
					39 00 00 40 00 00 04 B0 00 D8 BF
					39 00 00 40 00 00 27 BF 00 00 3F EC 3F CE 3F CE 3F 9C 3F 9C 3F B0 3F 9C 3F D8 00 58 00 58 00 48 00 58 00 48 00 58 00 58 00 40 00 58 00 58
					39 00 00 40 00 00 1B C0 00 58 00 58 00 58 00 58 00 58 00 58 00 58 00 58 00 58 00 58 00 58 00 58 00 58
					39 00 00 40 00 00 04 B0 00 1A C0
					39 00 00 40 00 00 41 C0 00 00 3F EC 3F CE 3F CE 3F 9C 3F 9C 3F B0 3F 9C 3F D8 00 58 00 58 00 48 00 58 00 48 00 58 00 58 00 40 00 58 00 58 00 58 00 58 00 58 00 58 00 58 00 58 00 58 00 58 00 58 00 58 00 58 00 58 00 58
					39 00 00 40 00 00 04 B0 00 5A C0
					39 00 00 40 00 00 41 C0 00 00 3F EC 3F CE 3F CE 3F 9C 3F 9C 3F B0 3F 9C 3F D8 00 58 00 58 00 48 00 58 00 48 00 58 00 58 00 40 00 58 00 58 00 58 00 58 00 58 00 58 00 58 00 58 00 58 00 58 00 58 00 58 00 58 00 58 00 58
					15 00 00 40 00 00 02 F7 0F
					39 00 00 00 00 00 03 F0 A5 A5
				];
				qcom,mdss-dsi-pwm-state-l3tol1-command = [
					39 00 00 40 00 00 03 F0 5A 5A
					39 00 00 40 00 00 04 B0 00 D7 BF
					15 00 00 40 00 00 02 BF 01
					39 00 00 40 00 00 04 B0 00 9A C0
					39 00 00 40 00 00 61 C0 00 04 08 10 18 20 28 38 48 58 68 78 88 98 A8 B8 C8 D8 E8 EC FC FE FF FF FF FF FF FF FF FF FF FF 00 04 08 10 18 20 28 38 48 58 68 78 88 98 A8 B8 C8 D8 E8 EC FC FE FF FF FF FF FF FF FF FF FF FF 00 04 08 10 18 20 28 38 48 58 68 78 88 98 A8 B8 C8 D8 E8 EC FC FE FF FF FF FF FF FF FF FF FF FF
					39 00 00 40 00 00 04 B0 00 D8 BF
					39 00 00 40 00 00 27 BF 00 00 00 01 00 01 00 01 00 01 00 01 00 01 3F EC 3F F6 3F DD 3F DD 3F C9 3F E4 3F E4 3F C4 3F CE 3F CE 3F CE 3F CE
					39 00 00 40 00 00 1B C0 3F CE 3F CE 3F CE 3F CE 3F CE 3F CE 3F CE 3F CE 3F CE 3F CE 3F CE 3F CE 3F CE
					39 00 00 40 00 00 04 B0 00 1A C0
					39 00 00 40 00 00 41 C0 00 00 00 01 00 01 00 01 00 01 00 01 00 01 3F EC 3F F6 3F DD 3F DD 3F C9 3F E4 3F E4 3F C4 3F CE 3F CE 3F CE 3F CE 3F CE 3F CE 3F CE 3F CE 3F CE 3F CE 3F CE 3F CE 3F CE 3F CE 3F CE 3F CE 3F CE
					39 00 00 40 00 00 04 B0 00 5A C0
					39 00 00 40 00 00 41 C0 00 00 00 01 00 01 00 01 00 01 00 01 00 01 3F EC 3F F6 3F DD 3F DD 3F C9 3F E4 3F E4 3F C4 3F E4 3F E4 3F E4 3F E4 3F E4 3F E4 3F E4 3F E4 3F E4 3F E4 3F E4 3F E4 3F E4 3F E4 3F E4 3F E4 3F E4
					15 00 00 40 00 00 02 F7 0F
					39 00 00 00 00 00 03 F0 A5 A5
				];
				qcom,mdss-dsi-pwm-dbv-threshold-extend-command = [
					39 00 00 40 00 00 03 F0 5A 5A
					39 00 00 40 00 00 04 B0 00 D7 BF
					15 00 00 40 00 00 02 BF 00
					15 00 00 40 00 00 02 F7 0F
					39 00 00 00 00 00 03 F0 A5 A5
				];

				qcom,mdss-dsi-timming-pwm-switch-onepulse-command = [
					/* Level 2/3 key Enable */
					39 00 00 40 00 00 03 F0 5A 5A
					39 00 00 40 00 00 03 FC 5A 5A
					/* Sync_TE Setting: Fixed TE */
					39 00 00 40 00 00 04 B0 00 C6 D5
					39 00 00 40 00 00 02 D5 00
					39 00 00 40 00 00 04 B0 00 04 F4
					15 00 00 40 00 00 02 F4 0A
					39 00 00 40 00 00 04 B0 00 DB D5
					39 00 00 40 00 00 05 D5 00 B0 0C 30			/* 0x00 : Changeable TE */
					39 00 00 40 00 00 04 B0 00 E8 D5
					15 00 00 40 00 00 02 D5 00					/* 0x00 : 120Hz */
					/* Frequency Setting */
					39 00 00 40 00 00 03 60 00 00				/* 0x08 : 120Hz(1cyc) */
					/* Insert Valid Freq.Setting */
					39 00 00 40 00 00 04 B0 00 88 E4
					39 00 00 40 00 00 05 E4 00 03 00 03
					/* HOP Auto Mode OFF */
					39 00 00 40 00 00 04 B0 00 A9 E4
					15 00 00 40 00 00 02 E4 00					/* 0x00: Auto Off , 0x01: Auto On */
					/* Force Increasing OFF */
					39 00 00 40 00 00 04 B0 00 F4 E4
					15 00 00 40 00 00 02 E4 22					/* 0x00: On , 0x22: Off */
					39 00 00 40 00 00 04 B0 00 65 E4
					39 00 00 40 00 00 06 E4 00 00 00 00 00
					15 00 00 40 00 00 02 F7 0F
					/* Level 2/3 key Disable */
					39 00 00 40 00 00 03 F0 A5 A5
					39 00 00 00 00 00 03 FC A5 A5
				];
				qcom,mdss-dsi-pwm-switch-mode0-command = [
					/* Level 2/3 key Enable */
					39 00 00 40 00 00 03 F0 5A 5A
					39 00 00 40 00 00 03 FC 5A 5A
					/* Sync_TE Setting: Fixed TE */
					39 00 00 40 00 00 04 B0 00 C6 D5
					39 00 00 40 00 00 02 D5 00
					39 00 00 40 00 00 04 B0 00 04 F4
					15 00 00 40 00 00 02 F4 0A
					39 00 00 40 00 00 04 B0 00 DB D5
					39 00 00 40 00 00 05 D5 00 B0 0C 30			/* 0x00 : Changeable TE */
					39 00 00 40 00 00 04 B0 00 E8 D5
					15 00 00 40 00 00 02 D5 00					/* 0x00 : 120Hz */
					/* Frequency Setting */
					39 00 00 40 00 00 03 60 00 08				/* 0x08 : 120Hz(1/18cyc) */
					/* HOP Auto Mode OFF */
					39 00 00 40 00 00 04 B0 00 A9 E4
					15 00 00 40 00 00 02 E4 00					/* 0x00: Auto Off , 0x01: Auto On */
					/* Force Increasing OFF */
					39 00 00 40 00 00 04 B0 00 F4 E4
					15 00 00 40 00 00 02 E4 22					/* 0x00: On , 0x22: Off */
					39 00 00 40 00 00 04 B0 00 65 E4
					39 00 00 40 00 00 06 E4 00 00 00 00 00
					15 00 00 40 00 00 02 F7 0F
					/* Level 2/3 key Disable */
					39 00 00 40 00 00 03 F0 A5 A5
					39 00 00 00 00 00 03 FC A5 A5
				];
				qcom,mdss-dsi-pwm-switch-mode1-command = [
					/* Level 2/3 key Enable */
					39 00 00 40 00 00 03 F0 5A 5A
					39 00 00 40 00 00 03 FC 5A 5A
					/* Sync_TE Setting: Fixed TE */
					39 00 00 40 00 00 04 B0 00 C6 D5
					39 00 00 40 00 00 02 D5 00
					39 00 00 40 00 00 04 B0 00 04 F4
					15 00 00 40 00 00 02 F4 0A
					39 00 00 40 00 00 04 B0 00 DB D5
					39 00 00 40 00 00 05 D5 00 B0 0C 30			/* 0x00 : Changeable TE */
					39 00 00 40 00 00 04 B0 00 E8 D5
					15 00 00 40 00 00 02 D5 00					/* 0x00 : 120Hz */
					/* Frequency Setting */
					39 00 00 40 00 00 03 60 00 00				/* 0x08 : 120Hz(1cyc) */
					/* HOP Auto Mode OFF */
					39 00 00 40 00 00 04 B0 00 A9 E4
					15 00 00 40 00 00 02 E4 00					/* 0x00: Auto Off , 0x01: Auto On */
					/* Force Increasing OFF */
					39 00 00 40 00 00 04 B0 00 F4 E4
					15 00 00 40 00 00 02 E4 22					/* 0x00: On , 0x22: Off */
					39 00 00 40 00 00 04 B0 00 65 E4
					39 00 00 40 00 00 06 E4 00 00 00 00 00
					15 00 00 40 00 00 02 F7 0F
					/* Level 2/3 key Disable */
					39 00 00 40 00 00 03 F0 A5 A5
					39 00 00 00 00 00 03 FC A5 A5
				];
				qcom,mdss-dsi-pwm-switch-mode1-panel-on-command = [
					/* Level 2/3 key Enable */
					39 00 00 40 00 00 03 F0 5A 5A
					39 00 00 40 00 00 03 FC 5A 5A
					/* Sync_TE Setting: Fixed TE */
					39 00 00 40 00 00 04 B0 00 C6 D5
					39 00 00 40 00 00 02 D5 00
					39 00 00 40 00 00 04 B0 00 04 F4
					15 00 00 40 00 00 02 F4 0A
					39 00 00 40 00 00 04 B0 00 DB D5
					39 00 00 40 00 00 05 D5 00 B0 0C 30			/* 0x00 : Changeable TE */
					39 00 00 40 00 00 04 B0 00 E8 D5
					15 00 00 40 00 00 02 D5 00					/* 0x00 : 120Hz */
					/* Frequency Setting */
					39 00 00 40 00 00 03 60 00 00				/* 0x08 : 120Hz(1cyc) */
					/* HOP Auto Mode OFF */
					39 00 00 40 00 00 04 B0 00 A9 E4
					15 00 00 40 00 00 02 E4 00					/* 0x00: Auto Off , 0x01: Auto On */
					/* Force Increasing OFF */
					39 00 00 40 00 00 04 B0 00 F4 E4
					15 00 00 40 00 00 02 E4 22					/* 0x00: On , 0x22: Off */
					39 00 00 40 00 00 04 B0 00 65 E4
					39 00 00 40 00 00 06 E4 00 00 00 00 00
					15 00 00 40 00 00 02 F7 0F
					/* Level 2/3 key Disable */
					39 00 00 40 00 00 03 F0 A5 A5
					39 00 00 00 00 00 03 FC A5 A5
				];

			};


		};
	};
};

&soc {
	dsi_panel_AB849_P_1_A0022_dsc_cmd {
		qcom,dsi-display-active;
	};
};

&dsi_panel_AB849_P_1_A0022_dsc_cmd {
	qcom,ulps-enabled;
	qcom,dsi-select-clocks = "pll_byte_clk0", "pll_dsi_clk0";
	qcom,mdss-dsi-display-timings {
		timing@sa_fhd_60 {
			qcom,mdss-dsi-panel-phy-timings = [00 24 0A 0A 1A 24 0A 0A 09 02 04 00 1E 0F];
			qcom,display-topology = <1 1 1>,<2 2 1>;
			qcom,default-topology-index = <1>;
		};
		timing@sa_fhd_120 {
			qcom,mdss-dsi-panel-phy-timings = [00 24 0A 0A 1A 24 0A 0A 09 02 04 00 1E 0F];
			qcom,display-topology = <1 1 1>,<2 2 1>;
			qcom,default-topology-index = <1>;
		};
		timing@oa_fhd_120 {
			qcom,mdss-dsi-panel-phy-timings = [00 24 0A 0A 1A 24 0A 0A 09 02 04 00 1E 0F];
			qcom,display-topology = <1 1 1>,<2 2 1>;
			qcom,default-topology-index = <1>;
		};
	};
};

&dsi_panel_AB849_P_1_A0022_dsc_cmd {
	/* HARDWARE CONFIG */
	qcom,panel-supply-entries = <&oplus_dsi_panel_custom_pwr_supply>;
	qcom,mdss-dsi-panel-controller = <&mdss_dsi0>;
	qcom,platform-te-gpio = <&tlmm 86 0>;
	qcom,platform-reset-gpio = <&tlmm 98 0>;
	oplus,panel-gpio1  = <&pm8550ve_f_gpios 7 0>;

	oplus,panel-reset-position = <0x02>;
	oplus,panel-power-on-sequence = "3", "vddio", "3", "gpio1", "3", "vci", "10";
	oplus,panel-power-off-sequence = "10", "vci", "3", "gpio1", "3", "vddio", "3";

	qcom,panel_voltage_vddi_name = "vddio";
	qcom,panel_voltage_vddi = <1 1750000 1850000 1950000>;
	qcom,panel_voltage_vddr_name = "vci";
	qcom,panel_voltage_vddr = <1 3000000 3200000 3300000>;

	//enable mipi strength
	//oplus,enhance_mipi_strength;

	/* BRIGHTNESS CONFIG */
	qcom,mdss-dsi-bl-pmic-control-type = "bl_ctrl_dcs";
	qcom,bl-dsc-cmd-state = "dsi_hs_mode";
	qcom,mdss-dsi-bl-inverted-dbv;
	qcom,mdss-dsi-bl-min-level = <1>;
	qcom,mdss-dsi-bl-max-level = <4094>;
	qcom,mdss-brightness-max-level = <4094>;
	oplus,dsi-dc-backlight-threshold = <1960>;
	oplus,dsi-bl-normal-max-level = <3332>;
	oplus,dsi-brightness-normal-max-level = <3332>;
	oplus,dsi-brightness-default-level = <1433>;

	/* ESD CONFIG */
	qcom,esd-check-enabled;
	qcom,mdss-dsi-panel-status-check-mode = "reg_read";
	qcom,mdss-dsi-panel-status-command = [
		06 00 00 00 00 00 01 0A
		06 00 00 00 00 00 01 0F
	];
	qcom,mdss-dsi-panel-status-command-state = "dsi_lp_mode";
	qcom,mdss-dsi-panel-status-value = <
		0x9C 0x00
		0x9C 0x40
		0x9C 0x80
		0x9C 0xC0
	>;
	qcom,mdss-dsi-panel-status-read-length = <1 1>;
	oplus,mdss-dsi-panel-status-match-modes = <0x00000000>;

	/* FACTORY CONFIG */
	oplus,color_vivid_status;
	oplus,color_srgb_status;
	oplus,color_oplus_calibrate_status;
	oplus,color_dual_brightness_status;
	oplus,color_samsung_status;
	oplus,color_loading_status;
	oplus,color_2nit_status;
	oplus,mdss-dsi-panel-type = <1>;

	/* OPLUS FEATURES CONFIG */
	oplus,dp-enabled;

	oplus,dsi-serial-number-enabled;
	oplus,dsi-serial-number-switch-page;
	oplus,dsi-serial-number-reg= <0xA1>;
	oplus,dsi-serial-number-index= <10>;
	oplus,dsi-serial-number-read-count= <17>;

	oplus,dsi-panel-id-switch-page;

	/* adfr config */
	oplus,adfr-config = <0x1051>;  //0b 0001 0000 0101 0001
	oplus,adfr-test-te-gpio = <&tlmm 85 0>;
	/* just for qsync enable */
	qcom,qsync-enable;
	qcom,mdss-dsi-qsync-min-refresh-rate = <24>;

	/* ofp config */
	oplus,ofp-fp-type = <0xC0>;
	oplus,ofp-longrui-aod-config = <0x02>;
	oplus,ofp-need-to-bypass-gamut;
	oplus,ofp-need-to-wait-data-before-aod-on;
	oplus,ofp-need-to-wait-te-before-aod-on;
	oplus,ofp-need-to-wait-sometime-before-aod-off;

	/* pwm config */
	/*	oplus,pwm-switch-config:
		Bit0: pwm feature enable
		Bit1: pwm mode switch enable, need to config switch cmds
		Bit2: force enabled pwm mode switch cmd, will send mode cmd even dbv threshold cmd feature is configed
		Bit3: pwm dbv threshold pulse switch enable, need to config threshold switch cmds
		Bit4: wait te before sending pwm dbv threshold pulse switch cmd
		Bit5: replace specific cmd to other cmd while in pwm 1pulse mode
		Bit6: sending extend cmd while panel power on accroding to current pwm mode
		Bit7: sending extend cmd while timing switch accroding to current pwm pulse level
		Bit8: sending extend cmd after sending dbv threshold cmd in another thread
	*/
	oplus,pwm-switch-config = <0x17F>;//0b 1 0110 1111

	/*	oplus,pwm-switch-mode0-states-info/oplus,pwm-switch-mode1-states-info:
		Specific dbv threshold and pulse info of 2 pwm mode, for pulse, 0 symbols 1pulse,
		1symbols 3pulse and 2 symbols 18pulse. The format should be 1 dbv threshold info with
		2 pwm pulse levels left and right(for example, <2 1087 1> means 18pulse while dbv <= 1087
		and 3pulse while dbv > 1087), or only one pulse level, no threshold.
	*/
	oplus,pwm-switch-mode0-states-info = <2 954 0>;
	oplus,pwm-switch-mode1-states-info = <0>;
	/*	oplus,pwm-cmd-switch-map:
		Specific cmd replace relationship while in switch on(1pulse) mode. It is a string array that
		compose with cmd names, every 2 names combine 1 map. For example, map "'a', 'b'" means replace
		a to b while sending a in switch on mode.
	*/
	oplus,pwm-cmd-switch-map = "qcom,mdss-dsi-timing-switch-command", "qcom,mdss-dsi-timming-pwm-switch-onepulse-command";

};
